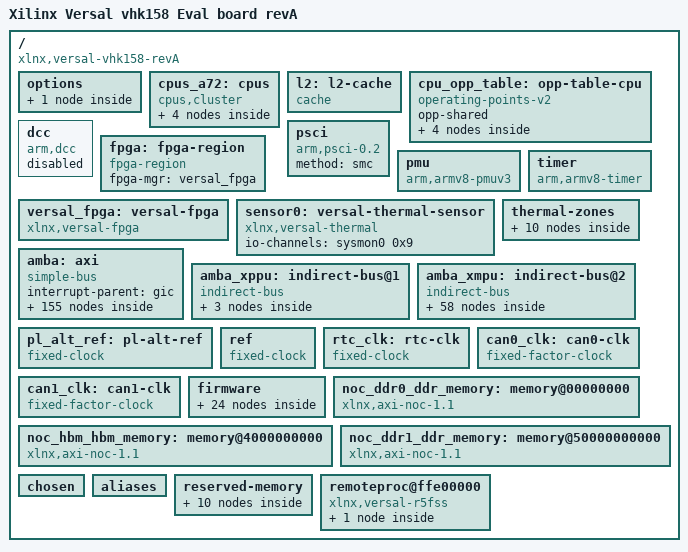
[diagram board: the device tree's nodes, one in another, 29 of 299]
/dts-v1/;
/ {
        speed_grade = "2MP";
        family = "Versal";
        slrcount = <0x2>;
        device_id = "xcvh1582";
        vivado-version = "2026.2";
        board = "vhk158";
        model = "Xilinx Versal vhk158 Eval board revA";
        #size-cells = <0x2>;
        #address-cells = <0x2>;
        compatible = "xlnx,versal-vhk158-revA", "xlnx,versal-vhk158", "xlnx,versal";

        options {

                u-boot {
                        bootscr-address = /bits/ 64 <0x20000000>;
                        compatible = "u-boot,config";
                };
        };

        cpus_a72: cpus {
                phandle = <0xc6>;
                #ranges-size-cells = <0x2>;
                #ranges-address-cells = <0x2>;
                compatible = "cpus,cluster";
                #size-cells = <0x0>;
                #address-cells = <0x1>;

                psv_cortexa72_0: cpu@0 {
                        phandle = <0xbf>;
                        bus-handle = <0x1>;
                        cpu-frequency = <0x5372172a>;
                        xlnx,cpu-clk-freq-hz = <0x5372172a>;
                        xlnx,ip-name = "psv_cortexa72";
                        stamp-frequency = <0x5f5dd19>;
                        xlnx,pss-ref-clk-freq = <0x1fc9f08>;
                        xlnx,timestamp-clk-freq = <0x5f5dd19>;
                        clocks = <&versal_clk 0x4d>;
                        next-level-cache = <&l2>;
                        i-cache-sets = <0x100>;
                        i-cache-line-size = <0x40>;
                        i-cache-size = <0xc000>;
                        d-cache-sets = <0x100>;
                        d-cache-line-size = <0x40>;
                        d-cache-size = <0x8000>;
                        power-domains = <&versal_firmware 0x18110003>;
                        cpu-idle-states = <&CPU_SLEEP_0>;
                        reg = <0x0>;
                        operating-points-v2 = <&cpu_opp_table>;
                        enable-method = "psci";
                        device_type = "cpu";
                        compatible = "arm,cortex-a72", "arm,armv8";
                };

                psv_cortexa72_1: cpu@1 {
                        phandle = <0xc1>;
                        bus-handle = <0x1>;
                        cpu-frequency = <0x5372172a>;
                        xlnx,cpu-clk-freq-hz = <0x5372172a>;
                        xlnx,ip-name = "psv_cortexa72";
                        stamp-frequency = <0x5f5dd19>;
                        xlnx,pss-ref-clk-freq = <0x1fc9f08>;
                        xlnx,timestamp-clk-freq = <0x5f5dd19>;
                        next-level-cache = <&l2>;
                        i-cache-sets = <0x100>;
                        i-cache-line-size = <0x40>;
                        i-cache-size = <0xc000>;
                        d-cache-sets = <0x100>;
                        d-cache-line-size = <0x40>;
                        d-cache-size = <0x8000>;
                        power-domains = <&versal_firmware 0x18110004>;
                        cpu-idle-states = <&CPU_SLEEP_0>;
                        reg = <0x1>;
                        operating-points-v2 = <&cpu_opp_table>;
                        enable-method = "psci";
                        device_type = "cpu";
                        compatible = "arm,cortex-a72", "arm,armv8";
                };

                idle-states {
                        entry-method = "psci";

                        CPU_SLEEP_0: cpu-sleep-0 {
                                phandle = <0x8f>;
                                min-residency-us = <0x2710>;
                                exit-latency-us = <0x258>;
                                entry-latency-us = <0x12c>;
                                local-timer-stop;
                                arm,psci-suspend-param = <0x40000000>;
                                compatible = "arm,idle-state";
                        };
                };
        };

        l2: l2-cache {
                phandle = <0x91>;
                cache-unified;
                cache-sets = <0x1000>;
                cache-line-size = <0x40>;
                cache-size = <0x100000>;
                cache-level = <0x2>;
                compatible = "cache";
        };

        cpu_opp_table: opp-table-cpu {
                phandle = <0x8e>;
                opp-shared;
                compatible = "operating-points-v2";

                opp-1400000000 {
                        opp-microvolt = <0xf4240>;
                        clock-latency-ns = <0x7a120>;
                        opp-hz = /bits/ 64 <0x53724e00>;
                };

                opp-700000000 {
                        opp-microvolt = <0xf4240>;
                        clock-latency-ns = <0x7a120>;
                        opp-hz = /bits/ 64 <0x29b92700>;
                };

                opp-466666667 {
                        opp-microvolt = <0xf4240>;
                        clock-latency-ns = <0x7a120>;
                        opp-hz = /bits/ 64 <0x1bd0c4ab>;
                };

                opp-350000000 {
                        opp-microvolt = <0xf4240>;
                        clock-latency-ns = <0x7a120>;
                        opp-hz = /bits/ 64 <0x14dc9380>;
                };
        };

        dcc: dcc {
                phandle = <0xcf>;
                bootph-all;
                status = "disabled";
                compatible = "arm,dcc";
        };

        fpga: fpga-region {
                phandle = <0xd0>;
                #size-cells = <0x2>;
                #address-cells = <0x2>;
                fpga-mgr = <&versal_fpga>;
                compatible = "fpga-region";
        };

        psci: psci {
                phandle = <0xd1>;
                method = "smc";
                compatible = "arm,psci-0.2";
        };

        pmu: pmu {
                phandle = <0x183>;
                interrupts = <0x1 0x7 0x304>;
                interrupt-parent = <&gic>;
                compatible = "arm,armv8-pmuv3";
        };

        timer: timer {
                phandle = <0xd2>;
                interrupts = <0x1 0xd 0x4 0x1 0xe 0x4 0x1 0xb 0x4 0x1 0xa 0x4>;
                interrupt-parent = <&gic>;
                compatible = "arm,armv8-timer";
        };

        versal_fpga: versal-fpga {
                phandle = <0xa9>;
                compatible = "xlnx,versal-fpga";
        };

        sensor0: versal-thermal-sensor {
                phandle = <0xab>;
                io-channel-names = "sysmon-temp-channel";
                io-channels = <&sysmon0 0x9>;
                #thermal-sensor-cells = <0x1>;
                compatible = "xlnx,versal-thermal";
        };

        thermal-zones {

                versal_thermal: versal-thermal {
                        phandle = <0xd3>;
                        thermal-sensors = <&sensor0 0x0>;
                        polling-delay = <0x3e8>;
                        polling-delay-passive = <0xfa>;

                        trips {

                                temp_alert: temp-alert {
                                        phandle = <0xd4>;
                                        type = "passive";
                                        hysteresis = <0x0>;
                                        temperature = <0x11170>;
                                };

                                ot_crit: ot-crit {
                                        phandle = <0xd5>;
                                        type = "critical";
                                        hysteresis = <0x0>;
                                        temperature = <0x1e848>;
                                };
                        };

                        cooling-maps {
                        };
                };

                versal_thermal_aie: versal-aie-thermal {
                        phandle = <0xd6>;
                        thermal-sensors = <&sensor0 0x1>;
                        polling-delay = <0x3e8>;
                        polling-delay-passive = <0xfa>;

                        trips {

                                temp_alert_aie: temp-alert-aie {
                                        phandle = <0xd7>;
                                        type = "passive";
                                        hysteresis = <0x0>;
                                        temperature = <0x11170>;
                                };

                                ot_crit_aie: ot-crit-aie {
                                        phandle = <0xd8>;
                                        type = "critical";
                                        hysteresis = <0x0>;
                                        temperature = <0x1e848>;
                                };
                        };

                        cooling-maps {
                        };
                };
        };

        amba: axi {
                phandle = <0x1>;
                bootph-all;
                interrupt-parent = <&gic>;
                ranges;
                #size-cells = <0x2>;
                #address-cells = <0x2>;
                compatible = "simple-bus";

                can0: can@ff060000 {
                        phandle = <0xd9>;
                        power-domains = <&versal_firmware 0x1822401f>;
                        clocks = <&can0_clk>,
                         <&versal_clk 0x52>;
                        tx-mailbox-count = <0x20>;
                        rx-fifo-depth = <0x40>;
                        clock-names = "can_clk", "s_axi_aclk";
                        interrupt-parent = <&gic>;
                        interrupts = <0x0 0x14 0x4>;
                        reg = <0x0 0xff060000 0x0 0x6000>;
                        status = "disabled";
                        compatible = "xlnx,canfd-2.0";
                };

                can1: can@ff070000 {
                        phandle = <0xda>;
                        power-domains = <&versal_firmware 0x18224020>;
                        clocks = <&can1_clk>,
                         <&versal_clk 0x52>;
                        tx-mailbox-count = <0x20>;
                        rx-fifo-depth = <0x40>;
                        clock-names = "can_clk", "s_axi_aclk";
                        interrupt-parent = <&gic>;
                        interrupts = <0x0 0x15 0x4>;
                        reg = <0x0 0xff070000 0x0 0x6000>;
                        status = "disabled";
                        compatible = "xlnx,canfd-2.0";
                };

                cci: cci@fd000000 {
                        phandle = <0x60>;
                        xlnx,ip-name = "psv_fpd_maincci";
                        #size-cells = <0x1>;
                        #address-cells = <0x1>;
                        ranges = <0x0 0x0 0xfd000000 0xa0000>;
                        reg = <0x0 0xfd000000 0x0 0x10000>;
                        status = "okay";
                        compatible = "arm,cci-500";

                        cci_pmu: pmu@10000 {
                                phandle = <0xdb>;
                                interrupts = <0x0 0x6a 0x4 0x0 0x6a 0x4 0x0 0x6a 0x4 0x0 0x6a 0x4 0x0 0x6a 0x4 0x0 0x6a 0x4 0x0 0x6a 0x4 0x0 0x6a 0x4>;
                                interrupt-parent = <&gic>;
                                reg = <0x10000 0x90000>;
                                compatible = "arm,cci-500-pmu,r0";
                        };
                };

                lpd_dma_chan0: dma-controller@ffa80000 {
                        phandle = <0x82>;
                        xlnx,dma-mode = <0x1>;
                        xlnx,ip-name = "psv_adma";
                        xlnx,is-cache-coherent = <0x0>;
                        power-domains = <&versal_firmware 0x18224035>;
                        clocks = <&versal_clk 0x51>,
                         <&versal_clk 0x52>;
                        xlnx,bus-width = <0x40>;
                        #dma-cells = <0x1>;
                        xlnx,dma-type = <0x1>;
                        clock-names = "clk_main", "clk_apb";
                        interrupt-parent = <&gic>;
                        interrupts = <0x0 0x3c 0x4>;
                        reg = <0x0 0xffa80000 0x0 0x1000>;
                        status = "okay";
                        compatible = "xlnx,zynqmp-dma-1.0";
                        iommus = <&smmu 0x210>;
                };

                lpd_dma_chan1: dma-controller@ffa90000 {
                        phandle = <0x83>;
                        xlnx,dma-mode = <0x1>;
                        xlnx,ip-name = "psv_adma";
                        xlnx,is-cache-coherent = <0x0>;
                        power-domains = <&versal_firmware 0x18224036>;
                        clocks = <&versal_clk 0x51>,
                         <&versal_clk 0x52>;
                        xlnx,bus-width = <0x40>;
                        #dma-cells = <0x1>;
                        xlnx,dma-type = <0x1>;
                        clock-names = "clk_main", "clk_apb";
                        interrupt-parent = <&gic>;
                        interrupts = <0x0 0x3d 0x4>;
                        reg = <0x0 0xffa90000 0x0 0x1000>;
                        status = "okay";
                        compatible = "xlnx,zynqmp-dma-1.0";
                        iommus = <&smmu 0x212>;
                };

                lpd_dma_chan2: dma-controller@ffaa0000 {
                        phandle = <0x84>;
                        xlnx,dma-mode = <0x1>;
                        xlnx,ip-name = "psv_adma";
                        xlnx,is-cache-coherent = <0x0>;
                        power-domains = <&versal_firmware 0x18224037>;
                        clocks = <&versal_clk 0x51>,
                         <&versal_clk 0x52>;
                        xlnx,bus-width = <0x40>;
                        #dma-cells = <0x1>;
                        xlnx,dma-type = <0x1>;
                        clock-names = "clk_main", "clk_apb";
                        interrupt-parent = <&gic>;
                        interrupts = <0x0 0x3e 0x4>;
                        reg = <0x0 0xffaa0000 0x0 0x1000>;
                        status = "okay";
                        compatible = "xlnx,zynqmp-dma-1.0";
                        iommus = <&smmu 0x214>;
                };

                lpd_dma_chan3: dma-controller@ffab0000 {
                        phandle = <0x85>;
                        xlnx,dma-mode = <0x1>;
                        xlnx,ip-name = "psv_adma";
                        xlnx,is-cache-coherent = <0x0>;
                        power-domains = <&versal_firmware 0x18224038>;
                        clocks = <&versal_clk 0x51>,
                         <&versal_clk 0x52>;
                        xlnx,bus-width = <0x40>;
                        #dma-cells = <0x1>;
                        xlnx,dma-type = <0x1>;
                        clock-names = "clk_main", "clk_apb";
                        interrupt-parent = <&gic>;
                        interrupts = <0x0 0x3f 0x4>;
                        reg = <0x0 0xffab0000 0x0 0x1000>;
                        status = "okay";
                        compatible = "xlnx,zynqmp-dma-1.0";
                        iommus = <&smmu 0x216>;
                };

                lpd_dma_chan4: dma-controller@ffac0000 {
                        phandle = <0x86>;
                        xlnx,dma-mode = <0x1>;
                        xlnx,ip-name = "psv_adma";
                        xlnx,is-cache-coherent = <0x0>;
                        power-domains = <&versal_firmware 0x18224039>;
                        clocks = <&versal_clk 0x51>,
                         <&versal_clk 0x52>;
                        xlnx,bus-width = <0x40>;
                        #dma-cells = <0x1>;
                        xlnx,dma-type = <0x1>;
                        clock-names = "clk_main", "clk_apb";
                        interrupt-parent = <&gic>;
                        interrupts = <0x0 0x40 0x4>;
                        reg = <0x0 0xffac0000 0x0 0x1000>;
                        status = "okay";
                        compatible = "xlnx,zynqmp-dma-1.0";
                        iommus = <&smmu 0x218>;
                };

                lpd_dma_chan5: dma-controller@ffad0000 {
                        phandle = <0x87>;
                        xlnx,dma-mode = <0x1>;
                        xlnx,ip-name = "psv_adma";
                        xlnx,is-cache-coherent = <0x0>;
                        power-domains = <&versal_firmware 0x1822403a>;
                        clocks = <&versal_clk 0x51>,
                         <&versal_clk 0x52>;
                        xlnx,bus-width = <0x40>;
                        #dma-cells = <0x1>;
                        xlnx,dma-type = <0x1>;
                        clock-names = "clk_main", "clk_apb";
                        interrupt-parent = <&gic>;
                        interrupts = <0x0 0x41 0x4>;
                        reg = <0x0 0xffad0000 0x0 0x1000>;
                        status = "okay";
                        compatible = "xlnx,zynqmp-dma-1.0";
                        iommus = <&smmu 0x21a>;
                };

                lpd_dma_chan6: dma-controller@ffae0000 {
                        phandle = <0x88>;
                        xlnx,dma-mode = <0x1>;
                        xlnx,ip-name = "psv_adma";
                        xlnx,is-cache-coherent = <0x0>;
                        power-domains = <&versal_firmware 0x1822403b>;
                        clocks = <&versal_clk 0x51>,
                         <&versal_clk 0x52>;
                        xlnx,bus-width = <0x40>;
                        #dma-cells = <0x1>;
                        xlnx,dma-type = <0x1>;
                        clock-names = "clk_main", "clk_apb";
                        interrupt-parent = <&gic>;
                        interrupts = <0x0 0x42 0x4>;
                        reg = <0x0 0xffae0000 0x0 0x1000>;
                        status = "okay";
                        compatible = "xlnx,zynqmp-dma-1.0";
                        iommus = <&smmu 0x21c>;
                };

                lpd_dma_chan7: dma-controller@ffaf0000 {
                        phandle = <0x89>;
                        xlnx,dma-mode = <0x1>;
                        xlnx,ip-name = "psv_adma";
                        xlnx,is-cache-coherent = <0x0>;
                        power-domains = <&versal_firmware 0x1822403c>;
                        clocks = <&versal_clk 0x51>,
                         <&versal_clk 0x52>;
                        xlnx,bus-width = <0x40>;
                        #dma-cells = <0x1>;
                        xlnx,dma-type = <0x1>;
                        clock-names = "clk_main", "clk_apb";
                        interrupt-parent = <&gic>;
                        interrupts = <0x0 0x43 0x4>;
                        reg = <0x0 0xffaf0000 0x0 0x1000>;
                        status = "okay";
                        compatible = "xlnx,zynqmp-dma-1.0";
                        iommus = <&smmu 0x21e>;
                };

                gem0: ethernet@ff0c0000 {
                        phandle = <0x72>;
                        phy-handle = <0xae>;
                        xlnx,enet-slcr-100mbps-div0 = <0xa>;
                        xlnx,enet-clk-freq-hz = <0x773545d>;
                        xlnx,eth-mode = <0x1>;
                        xlnx,ip-name = "psv_ethernet";
                        xlnx,enet-tsu-clk-freq-hz = <0xee6a8ba>;
                        xlnx,enet-slcr-10mbps-div0 = <0x64>;
                        xlnx,enet-slcr-1000mbps-div0 = <0x2>;
                        phy-mode = "rgmii-id";
                        xlnx,gem-board-interface = "custom";
                        xlnx,is-cache-coherent = <0x0>;
                        xlnx,has-mdio = <0x1>;
                        power-domains = <&versal_firmware 0x18224019>;
                        clocks = <&versal_clk 0x52>,
                         <&versal_clk 0x58>,
                         <&versal_clk 0x31>,
                         <&versal_clk 0x30>,
                         <&versal_clk 0x2b>;
                        #size-cells = <0x0>;
                        #address-cells = <0x1>;
                        clock-names = "pclk", "hclk", "tx_clk", "rx_clk", "tsu_clk";
                        interrupt-parent = <&gic>;
                        interrupts = <0x0 0x38 0x4 0x0 0x38 0x4>;
                        reg = <0x0 0xff0c0000 0x0 0x1000>;
                        status = "okay";
                        compatible = "xlnx,versal-gem", "cdns,gem";
                        iommus = <&smmu 0x234>;

                        mdio: mdio {
                                phandle = <0xdc>;
                                #size-cells = <0x0>;
                                #address-cells = <0x1>;

                                phy1: ethernet-phy@1 {
                                        phandle = <0xae>;
                                        reset-gpios = <&gpio1 0x30 0x1>;
                                        reset-deassert-us = <0x118>;
                                        reset-assert-us = <0x64>;
                                        ti,dp83867-rxctrl-strap-quirk;
                                        ti,fifo-depth = <0x1>;
                                        ti,tx-internal-delay = <0xa>;
                                        ti,rx-internal-delay = <0xb>;
                                        reg = <0x1>;
                                        compatible = "ethernet-phy-id2000.a231";
                                };
                        };
                };

                gem1: ethernet@ff0d0000 {
                        phandle = <0xdd>;
                        power-domains = <&versal_firmware 0x1822401a>;
                        clocks = <&versal_clk 0x52>,
                         <&versal_clk 0x59>,
                         <&versal_clk 0x33>,
                         <&versal_clk 0x32>,
                         <&versal_clk 0x2b>;
                        #size-cells = <0x0>;
                        #address-cells = <0x1>;
                        clock-names = "pclk", "hclk", "tx_clk", "rx_clk", "tsu_clk";
                        interrupt-parent = <&gic>;
                        interrupts = <0x0 0x3a 0x4 0x0 0x3a 0x4>;
                        reg = <0x0 0xff0d0000 0x0 0x1000>;
                        status = "disabled";
                        compatible = "xlnx,versal-gem", "cdns,gem";
                        iommus = <&smmu 0x235>;
                };

                gpio0: gpio@ff0b0000 {
                        phandle = <0xde>;
                        power-domains = <&versal_firmware 0x18224023>;
                        clocks = <&versal_clk 0x52>;
                        interrupt-controller;
                        #interrupt-cells = <0x2>;
                        gpio-controller;
                        #gpio-cells = <0x2>;
                        interrupt-parent = <&gic>;
                        interrupts = <0x0 0xd 0x4>;
                        reg = <0x0 0xff0b0000 0x0 0x1000>;
                        status = "disabled";
                        compatible = "xlnx,versal-gpio-1.0";
                };

                gpio1: gpio@f1020000 {
                        phandle = <0x35>;
                        xlnx,pmc-gpio-emio-peripheral-enable = <0x0>;
                        xlnx,ip-name = "psv_pmc_gpio";
                        power-domains = <&versal_firmware 0x1822402c>;
                        clocks = <&versal_clk 0x3d>;
                        interrupt-controller;
                        #interrupt-cells = <0x2>;
                        gpio-controller;
                        #gpio-cells = <0x2>;
                        interrupt-parent = <&gic>;
                        interrupts = <0x0 0x7a 0x4>;
                        reg = <0x0 0xf1020000 0x0 0x1000>;
                        status = "okay";
                        compatible = "xlnx,pmc-gpio-1.0";
                };

                i2c0: i2c@ff020000 {
                        phandle = <0x6e>;
                        xlnx,iic-board-interface = "custom";
                        xlnx,ip-name = "psv_i2c";
                        xlnx,i2c-clk-freq-hz = <0x5f5dd19>;
                        xlnx,clock-freq = <0x5f5dd19>;
                        power-domains = <&versal_firmware 0x1822401d>;
                        clocks = <&versal_clk 0x62>;
                        #size-cells = <0x0>;
                        #address-cells = <0x1>;
                        clock-frequency = <0x186a0>;
                        interrupt-parent = <&gic>;
                        interrupts = <0x0 0xe 0x4>;
                        reg = <0x0 0xff020000 0x0 0x1000>;
                        status = "okay";
                        compatible = "cdns,i2c-r1p14";
                };

                i2c1: i2c@ff030000 {
                        phandle = <0x6f>;
                        bootph-all;
                        xlnx,iic-board-interface = "custom";
                        xlnx,ip-name = "psv_i2c";
                        xlnx,i2c-clk-freq-hz = <0x5f5dd19>;
                        xlnx,clock-freq = <0x5f5dd19>;
                        power-domains = <&versal_firmware 0x1822401e>;
                        clocks = <&versal_clk 0x63>;
                        #size-cells = <0x0>;
                        #address-cells = <0x1>;
                        clock-frequency = <0x186a0>;
                        interrupt-parent = <&gic>;
                        interrupts = <0x0 0xf 0x4>;
                        reg = <0x0 0xff030000 0x0 0x1000>;
                        status = "okay";
                        compatible = "cdns,i2c-r1p14";

                        eeprom: eeprom@54 {
                                phandle = <0xdf>;
                                bootph-all;
                                reg = <0x54>;
                                compatible = "st,24c128", "atmel,24c128";
                        };
                };

                i2c2: i2c@f1000000 {
                        phandle = <0xe0>;
                        power-domains = <&versal_firmware 0x1822402d>;
                        clocks = <&versal_clk 0x3e>;
                        #size-cells = <0x0>;
                        #address-cells = <0x1>;
                        clock-frequency = <0x186a0>;
                        interrupt-parent = <&gic>;
                        interrupts = <0x0 0x7b 0x4>;
                        reg = <0x0 0xf1000000 0x0 0x1000>;
                        status = "disabled";
                        compatible = "cdns,i2c-r1p14";
                };

                mc0: memory-controller@f6150000 {
                        phandle = <0xe1>;
                        interrupt-parent = <&gic>;
                        interrupts = <0x0 0x93 0x4>;
                        reg-names = "base", "noc";
                        reg = <0x0 0xf6150000 0x0 0x2000 0x0 0xf6070000 0x0 0x20000>;
                        status = "okay";
                        compatible = "xlnx,versal-ddrmc";
                };

                mc1: memory-controller@f62c0000 {
                        phandle = <0xe2>;
                        interrupt-parent = <&gic>;
                        interrupts = <0x0 0x93 0x4>;
                        reg-names = "base", "noc";
                        reg = <0x0 0xf62c0000 0x0 0x2000 0x0 0xf6210000 0x0 0x20000>;
                        status = "okay";
                        compatible = "xlnx,versal-ddrmc";
                };

                mc2: memory-controller@f6430000 {
                        phandle = <0xe3>;
                        interrupt-parent = <&gic>;
                        interrupts = <0x0 0x93 0x4>;
                        reg-names = "base", "noc";
                        reg = <0x0 0xf6430000 0x0 0x2000 0x0 0xf6380000 0x0 0x20000>;
                        status = "disabled";
                        compatible = "xlnx,versal-ddrmc";
                };

                mc3: memory-controller@f65a0000 {
                        phandle = <0xe4>;
                        interrupt-parent = <&gic>;
                        interrupts = <0x0 0x93 0x4>;
                        reg-names = "base", "noc";
                        reg = <0x0 0xf65a0000 0x0 0x2000 0x0 0xf64f0000 0x0 0x20000>;
                        status = "disabled";
                        compatible = "xlnx,versal-ddrmc";
                };

                ocm: memory-controller@ff960000 {
                        phandle = <0xe5>;
                        interrupt-parent = <&gic>;
                        interrupts = <0x0 0xa 0x4>;
                        reg = <0x0 0xff960000 0x0 0x1000>;
                        compatible = "xlnx,zynqmp-ocmc-1.0";
                };

                rtc: rtc@f12a0000 {
                        phandle = <0x47>;
                        xlnx,ip-name = "psv_pmc_rtc";
                        power-domains = <&versal_firmware 0x18224034>;
                        clock-names = "rtc";
                        clocks = <&rtc_clk>;
                        interrupt-parent = <&gic>;
                        interrupts = <0x0 0x8e 0x4 0x0 0x8f 0x4>;
                        interrupt-names = "alarm", "sec";
                        reg = <0x0 0xf12a0000 0x0 0x100>;
                        status = "okay";
                        compatible = "xlnx,zynqmp-rtc";
                };

                sdhci0: mmc@f1040000 {
                        phandle = <0xe6>;
                        power-domains = <&versal_firmware 0x1822402e>;
                        clocks = <&versal_clk 0x3b>,
                         <&versal_clk 0x52>,
                         <&versal_clk 0x4a>;
                        clock-output-names = "clk_out_sd0", "clk_in_sd0";
                        #clock-cells = <0x1>;
                        clock-names = "clk_xin", "clk_ahb", "gate";
                        interrupt-parent = <&gic>;
                        interrupts = <0x0 0x7e 0x4>;
                        reg = <0x0 0xf1040000 0x0 0x10000>;
                        status = "disabled";
                        compatible = "xlnx,versal-8.9a", "arasan,sdhci-8.9a";
                        iommus = <&smmu 0x242>;
                };

                sdhci1: mmc@f1050000 {
                        phandle = <0x36>;
                        no-1-8-v;
                        xlnx,write-protect = <0x0>;
                        xlnx,sdio-clk-freq-hz = <0xbebba31>;
                        xlnx,clk-200-sdr-otap-dly = <0x2>;
                        xlnx,has-power = <0x1>;
                        xlnx,clk-50-ddr-itap-dly = <0x2a>;
                        xlnx,clk-50-sdr-otap-dly = <0x4>;
                        xlnx,slot-type = <0x4>;
                        xlnx,has-cd = <0x1>;
                        xlnx,has-wp = <0x0>;
                        xlnx,card-detect = <0x1>;
                        xlnx,bus-width = <0x8>;
                        xlnx,ip-name = "psv_pmc_sd";
                        xlnx,mio-bank = <0x1>;
                        xlnx,clk-100-sdr-otap-dly = <0x3>;
                        clock-frequency = <0xbebba31>;
                        xlnx,has-emio = <0x0>;
                        xlnx,clk-50-sdr-itap-dly = <0x25>;
                        xlnx,clk-50-ddr-otap-dly = <0x3>;
                        xlnx,is-cache-coherent = <0x0>;
                        xlnx,sd-board-interface = "custom";
                        power-domains = <&versal_firmware 0x1822402f>;
                        clocks = <&versal_clk 0x3c>,
                         <&versal_clk 0x52>,
                         <&versal_clk 0x4a>;
                        clock-output-names = "clk_out_sd1", "clk_in_sd1";
                        #clock-cells = <0x1>;
                        clock-names = "clk_xin", "clk_ahb", "gate";
                        interrupt-parent = <&gic>;
                        interrupts = <0x0 0x80 0x4>;
                        reg = <0x0 0xf1050000 0x0 0x10000>;
                        status = "okay";
                        compatible = "xlnx,versal-8.9a", "arasan,sdhci-8.9a";
                        iommus = <&smmu 0x243>;
                };

                serial0: serial@ff000000 {
                        phandle = <0x6d>;
                        xlnx,clock-freq = <0x5f5dd19>;
                        device_type = "serial";
                        u-boot,dm-pre-reloc;
                        cts-override;
                        xlnx,baudrate = <0x1c200>;
                        xlnx,uart-board-interface = "custom";
                        xlnx,ip-name = "psv_sbsauart";
                        port-number = <0x0>;
                        xlnx,uart-clk-freq-hz = <0x5f5dd19>;
                        xlnx,has-modem = <0x0>;
                        power-domains = <&versal_firmware 0x18224021>;
                        clocks = <&versal_clk 0x5c>,
                         <&versal_clk 0x52>;
                        bootph-all;
                        clock-names = "uartclk", "apb_pclk";
                        reg-io-width = <0x4>;
                        interrupt-parent = <&gic>;
                        interrupts = <0x0 0x12 0x4>;
                        reg = <0x0 0xff000000 0x0 0x1000>;
                        status = "okay";
                        compatible = "arm,pl011", "arm,primecell";
                };

                serial1: serial@ff010000 {
                        phandle = <0xe7>;
                        power-domains = <&versal_firmware 0x18224022>;
                        clocks = <&versal_clk 0x5d>,
                         <&versal_clk 0x52>;
                        bootph-all;
                        clock-names = "uartclk", "apb_pclk";
                        reg-io-width = <0x4>;
                        interrupt-parent = <&gic>;
                        interrupts = <0x0 0x13 0x4>;
                        reg = <0x0 0xff010000 0x0 0x1000>;
                        status = "disabled";
                        compatible = "arm,pl011", "arm,primecell";
                };

                smmu: iommu@fd800000 {
                        phandle = <0x6b>;
                        xlnx,ip-name = "psv_fpd_smmutcu";
                        interrupt-parent = <&gic>;
                        interrupts = <0x0 0x6b 0x4 0x0 0x6b 0x4 0x0 0x6b 0x4 0x0 0x6b 0x4 0x0 0x6b 0x4 0x0 0x6b 0x4 0x0 0x6b 0x4 0x0 0x6b 0x4 0x0 0x6b 0x4 0x0 0x6b 0x4 0x0 0x6b 0x4 0x0 0x6b 0x4 0x0 0x6b 0x4 0x0 0x6b 0x4 0x0 0x6b 0x4 0x0 0x6b 0x4 0x0 0x6b 0x4 0x0 0x6b 0x4 0x0 0x6b 0x4 0x0 0x6b 0x4 0x0 0x6b 0x4 0x0 0x6b 0x4 0x0 0x6b 0x4 0x0 0x6b 0x4 0x0 0x6b 0x4 0x0 0x6b 0x4 0x0 0x6b 0x4 0x0 0x6b 0x4 0x0 0x6b 0x4 0x0 0x6b 0x4 0x0 0x6b 0x4 0x0 0x6b 0x4 0x0 0x6b 0x4>;
                        #global-interrupts = <0x1>;
                        #iommu-cells = <0x1>;
                        stream-match-mask = <0x7c00>;
                        reg = <0x0 0xfd800000 0x0 0x40000>;
                        status = "disabled";
                        compatible = "arm,mmu-500";
                };

                ospi: spi@f1010000 {
                        phandle = <0x34>;
                        num-cs = <0x1>;
                        bus-num = <0x2>;
                        xlnx,ospi-mode = <0x0>;
                        is-dual = <0x0>;
                        xlnx,ospi-clk-freq-hz = <0xbebba31>;
                        xlnx,ip-name = "psv_pmc_ospi";
                        xlnx,clock-freq = <0xbebba31>;
                        xlnx,is-cache-coherent = <0x0>;
                        is-stacked = <0x0>;
                        resets = <&versal_reset 0xc10402e>;
                        reset-names = "qspi";
                        power-domains = <&versal_firmware 0x1822402a>;
                        clocks = <&versal_clk 0x3a>;
                        #size-cells = <0x0>;
                        #address-cells = <0x1>;
                        cdns,trigger-address = <0xc0000000>;
                        cdns,is-dma = <0x1>;
                        cdns,fifo-width = <0x4>;
                        cdns,fifo-depth = <0x100>;
                        interrupt-parent = <&gic>;
                        interrupts = <0x0 0x7c 0x4>;
                        reg = <0x0 0xf1010000 0x0 0x10000 0x0 0xc0000000 0x0 0x20000000>;
                        status = "okay";
                        compatible = "xlnx,versal-ospi-1.0", "cdns,qspi-nor";

                        spi_flash: flash@0 {
                                phandle = <0x2>;
                                reset-gpios = <&gpio1 0xc 0x1>;
                                no-wp;
                                spi-max-frequency = <0x1312d00>;
                                spi-rx-bus-width = <0x8>;
                                spi-tx-bus-width = <0x8>;
                                cdns,tslch-ns = <0x1>;
                                cdns,tchsh-ns = <0x1>;
                                cdns,tsd2d-ns = <0x0>;
                                cdns,tshsl-ns = <0x0>;
                                cdns,read-delay = <0x0>;
                                reg = <0x0>;
                                compatible = "mt35xu02g", "micron,m25p80", "jedec,spi-nor";

                                partitions {
                                        #size-cells = <0x1>;
                                        #address-cells = <0x1>;
                                        compatible = "fixed-partitions";

                                        partition@0 {
                                                reg = <0x0 0x60000>;
                                                label = "Image Selector";
                                        };

                                        partition@60000 {
                                                label = "Image Selector Backup";
                                                reg = <0x60000 0x60000>;
                                        };

                                        partition@c0000 {
                                                label = "Image Selector Scratchpad";
                                                reg = <0xc0000 0x20000>;
                                        };

                                        partition@e0000 {
                                                label = "Image Recovery";
                                                reg = <0xe0000 0x1400000>;
                                        };

                                        partition@14e0000 {
                                                label = "Image Recovery Scratchpad";
                                                reg = <0x14e0000 0x20000>;
                                        };

                                        partition@1500000 {
                                                label = "SystemReady-DT Update Metadata";
                                                reg = <0x1500000 0x20000>;
                                        };

                                        partition@1520000 {
                                                label = "SystemReady-DT Update Metadata Backup";
                                                reg = <0x1520000 0x20000>;
                                        };

                                        partition@1540000 {
                                                label = "U-Boot Variables";
                                                reg = <0x1540000 0x20000>;
                                        };

                                        partition@1560000 {
                                                label = "U-Boot Variables Backup";
                                                reg = <0x1560000 0x20000>;
                                        };

                                        partition@1580000 {
                                                label = "U-Boot UEFI Variables";
                                                reg = <0x1580000 0x40000>;
                                        };

                                        partition@15c0000 {
                                                label = "Bank A Space";
                                                reg = <0x15c0000 0x7200000>;
                                        };

                                        partition@87c0000 {
                                                label = "U-Boot Variables Bank A";
                                                reg = <0x87c0000 0x20000>;
                                        };

                                        partition@87e0000 {
                                                label = "U-Boot Variables Bank A Backup";
                                                reg = <0x87e0000 0x20000>;
                                        };

                                        partition@8800000 {
                                                label = "Bank B Space";
                                                reg = <0x8800000 0x7200000>;
                                        };

                                        partition@fa00000 {
                                                label = "U-Boot Variables Bank B";
                                                reg = <0xfa00000 0x20000>;
                                        };

                                        partition@fa20000 {
                                                label = "U-Boot Variables Bank B Backup";
                                                reg = <0xfa20000 0x20000>;
                                        };

                                        partition@fa40000 {
                                                label = "User Scratchpad";
                                                reg = <0xfa40000 0x5c0000>;
                                        };
                                };
                        };
                };

                qspi: spi@f1030000 {
                        phandle = <0xe8>;
                        power-domains = <&versal_firmware 0x1822402b>;
                        clocks = <&versal_clk 0x39>,
                         <&versal_clk 0x52>;
                        #size-cells = <0x0>;
                        #address-cells = <0x1>;
                        clock-names = "ref_clk", "pclk";
                        interrupt-parent = <&gic>;
                        interrupts = <0x0 0x7d 0x4>;
                        reg = <0x0 0xf1030000 0x0 0x1000>;
                        status = "disabled";
                        compatible = "xlnx,versal-qspi-1.0";
                        iommus = <&smmu 0x244>;
                };

                spi0: spi@ff040000 {
                        phandle = <0xe9>;
                        power-domains = <&versal_firmware 0x1822401b>;
                        clocks = <&versal_clk 0x5e>,
                         <&versal_clk 0x52>;
                        #size-cells = <0x0>;
                        #address-cells = <0x1>;
                        clock-names = "ref_clk", "pclk";
                        interrupt-parent = <&gic>;
                        interrupts = <0x0 0x10 0x4>;
                        reg = <0x0 0xff040000 0x0 0x1000>;
                        status = "disabled";
                        compatible = "cdns,spi-r1p6";
                };

                spi1: spi@ff050000 {
                        phandle = <0xea>;
                        power-domains = <&versal_firmware 0x1822401c>;
                        clocks = <&versal_clk 0x5f>,
                         <&versal_clk 0x52>;
                        #size-cells = <0x0>;
                        #address-cells = <0x1>;
                        clock-names = "ref_clk", "pclk";
                        interrupt-parent = <&gic>;
                        interrupts = <0x0 0x11 0x4>;
                        reg = <0x0 0xff050000 0x0 0x1000>;
                        status = "disabled";
                        compatible = "cdns,spi-r1p6";
                };

                sysmon0: sysmon@f1270000 {
                        phandle = <0x46>;
                        xlnx,sat-5-y = <0x1e46>;
                        xlnx,sat-13-y = <0x65f>;
                        xlnx,sat-5-x = <0x5955>;
                        xlnx,sat-13-x = <0x4517>;
                        xlnx,sat-23-desc = "VNOC , satellite";
                        xlnx,sat-4-desc = "VNOC , satellite";
                        xlnx,sat-1-y = <0x38d>;
                        xlnx,sat-63-y = <0xb4d>;
                        xlnx,sat-11-desc = "Clocking , column , satellite";
                        xlnx,meas-8 = "VP_VN";
                        xlnx,meas-4-slr-number = <0x0>;
                        xlnx,sat-1-x = <0x5f>;
                        xlnx,sat-63-x = <0x5f>;
                        xlnx,meas-7 = "VCC_PSLP";
                        xlnx,sat-25-y = <0x2210>;
                        xlnx,meas-6 = "VCC_PSFP";
                        xlnx,sat-25-x = <0xa4a>;
                        xlnx,sat-26-desc = "Clocking , column , satellite";
                        xlnx,meas-5 = "VCC_PMC";
                        xlnx,sat-7-desc = "Clocking , column , satellite";
                        xlnx,meas-4 = "VCCAUX_PMC";
                        xlnx,sat-14-desc = "VNOC , satellite";
                        xlnx,meas-3 = "VCC_SOC";
                        xlnx,sat-21-y = <0x65f>;
                        xlnx,meas-2 = "VCC_RAM";
                        xlnx,sat-21-x = <0x1c9b>;
                        xlnx,meas-1 = "VCCINT";
                        xlnx,meas-0 = "VCCAUX";
                        xlnx,sat-8-y = <0x1be2>;
                        xlnx,sat-16-y = <0x3670>;
                        xlnx,sat-8-x = <0x69c9>;
                        xlnx,sat-16-x = <0x44d5>;
                        xlnx,sat-17-desc = "VNOC , satellite";
                        xlnx,meas-1-slr-number = <0x0>;
                        xlnx,sat-4-y = <0x1252>;
                        xlnx,sat-12-y = <0x3fa>;
                        xlnx,sat-4-x = <0x5955>;
                        xlnx,sat-12-x = <0x69c9>;
                        xlnx,meas-6-slr-number = <0x0>;
                        xlnx,sat-28-y = <0xfee>;
                        xlnx,sat-21-desc = "VNOC , satellite";
                        xlnx,sat-28-x = <0xa4a>;
                        xlnx,sat-2-desc = "PMC , user , ADC";
                        xlnx,sat-64-desc = "PS , LPD , satellite";
                        xlnx,sat-24-y = <0x3670>;
                        xlnx,sat-24-x = <0x199c>;
                        xlnx,sat-24-desc = "HBM , Satellite , (left)";
                        xlnx,sat-5-desc = "VNOC , satellite";
                        xlnx,sat-19-y = <0x1e46>;
                        xlnx,sat-20-y = <0x3670>;
                        xlnx,sat-12-desc = "Clocking , column , satellite";
                        xlnx,sat-19-x = <0x30d9>;
                        xlnx,sat-20-x = <0x2f36>;
                        xlnx,meas-3-slr-number = <0x0>;
                        xlnx,sat-27-desc = "Clocking , column , satellite";
                        xlnx,sat-7-y = <0x2210>;
                        xlnx,sat-15-y = <0x1e46>;
                        xlnx,sat-7-x = <0x69c9>;
                        xlnx,sat-8-desc = "Clocking , column , satellite";
                        xlnx,sat-15-x = <0x4517>;
                        xlnx,sat-15-desc = "VNOC , satellite";
                        xlnx,meas-8-slr-number = <0x0>;
                        status = "okay";
                        xlnx,sat-3-y = <0x65f>;
                        xlnx,sat-11-y = <0xa29>;
                        xlnx,sat-3-x = <0x5955>;
                        xlnx,sat-11-x = <0x69c9>;
                        xlnx,sat-27-y = <0x161d>;
                        xlnx,sat-27-x = <0xa4a>;
                        xlnx,sat-18-desc = "VNOC , satellite";
                        xlnx,sat-23-y = <0x1e46>;
                        xlnx,meas-0-slr-number = <0x0>;
                        xlnx,sat-23-x = <0x1c9b>;
                        xlnx,sat-22-desc = "VNOC , satellite";
                        xlnx,meas-5-slr-number = <0x0>;
                        xlnx,sat-18-y = <0x1252>;
                        xlnx,sat-3-desc = "VNOC , satellite";
                        xlnx,sat-18-x = <0x30d9>;
                        xlnx,sat-10-desc = "Clocking , column , satellite";
                        xlnx,sat-6-y = <0x3670>;
                        xlnx,sat-14-y = <0x1252>;
                        xlnx,sat-25-desc = "Clocking , column , satellite";
                        xlnx,sat-6-x = <0x5a6e>;
                        xlnx,sat-14-x = <0x4517>;
                        xlnx,sat-6-desc = "HBM , Satellite , (right)";
                        xlnx,meas-8-root-id = <0x8>;
                        xlnx,sat-13-desc = "VNOC , satellite";
                        xlnx,meas-7-root-id = <0x5>;
                        xlnx,sat-2-y = <0x38d>;
                        xlnx,sat-64-y = <0xb4d>;
                        xlnx,sat-10-y = <0xfee>;
                        xlnx,meas-6-root-id = <0x4>;
                        xlnx,sat-2-x = <0x5f>;
                        xlnx,sat-64-x = <0x5f>;
                        xlnx,sat-10-x = <0x69c9>;
                        xlnx,meas-5-root-id = <0x3>;
                        xlnx,sat-26-y = <0x1be2>;
                        xlnx,sat-28-desc = "Clocking , column , satellite";
                        xlnx,meas-4-root-id = <0x1>;
                        xlnx,sat-26-x = <0xa4a>;
                        xlnx,sat-9-desc = "Clocking , column , satellite";
                        xlnx,meas-3-root-id = <0x7>;
                        xlnx,meas-2-slr-number = <0x0>;
                        xlnx,meas-2-root-id = <0x6>;
                        xlnx,sat-16-desc = "HBM , Satellite , (left)";
                        xlnx,ip-name = "psv_pmc_sysmon";
                        xlnx,meas-1-root-id = <0x2>;
                        xlnx,sat-22-y = <0x1252>;
                        xlnx,meas-7-slr-number = <0x0>;
                        xlnx,meas-0-root-id = <0x0>;
                        xlnx,sat-22-x = <0x1c9b>;
                        xlnx,sat-9-y = <0x161d>;
                        xlnx,sat-17-y = <0x65f>;
                        xlnx,sat-19-desc = "VNOC , satellite";
                        xlnx,sat-20-desc = "HBM , Satellite , (right)";
                        xlnx,sat-9-x = <0x69c9>;
                        xlnx,sat-17-x = <0x30d9>;
                        xlnx,sat-1-desc = "PMC , system , ADC";
                        xlnx,sat-63-desc = "PS , FPD , satellite";
                        xlnx,nodeid = <0x18224055>;
                        #size-cells = <0x2>;
                        #address-cells = <0x2>;
                        xlnx,numchannels = [09];
                        interrupts = <0x0 0x90 0x4>;
                        reg = <0x0 0xf1270000 0x0 0x4000>;
                        #io-channel-cells = <0x1>;
                        compatible = "xlnx,versal-sysmon";

                        supply@0 {
                                xlnx,name = "vccaux";
                                reg = <0x0>;
                        };

                        supply@2 {
                                xlnx,name = "vccint";
                                reg = <0x2>;
                        };

                        supply@6 {
                                xlnx,name = "vcc_ram";
                                reg = <0x6>;
                        };

                        supply@7 {
                                xlnx,name = "vcc_soc";
                                reg = <0x7>;
                        };

                        supply@1 {
                                xlnx,name = "vccaux_pmc";
                                reg = <0x1>;
                        };

                        supply@3 {
                                xlnx,name = "vcc_pmc";
                                reg = <0x3>;
                        };

                        supply@4 {
                                xlnx,name = "vcc_psfp";
                                reg = <0x4>;
                        };

                        supply@5 {
                                xlnx,name = "vcc_pslp";
                                reg = <0x5>;
                        };

                        supply@8 {
                                xlnx,name = "vp_vn";
                                reg = <0x8>;
                        };
                };

                sysmon1: sysmon@109270000 {
                        phandle = <0xeb>;
                        xlnx,nodeid = <0x18225055>;
                        #size-cells = <0x0>;
                        #address-cells = <0x1>;
                        xlnx,numchannels = [00];
                        reg = <0x1 0x9270000 0x0 0x4000>;
                        #io-channel-cells = <0x1>;
                        status = "disabled";
                        compatible = "xlnx,versal-sysmon";
                };

                sysmon2: sysmon@111270000 {
                        phandle = <0xec>;
                        xlnx,nodeid = <0x18226055>;
                        #size-cells = <0x0>;
                        #address-cells = <0x1>;
                        xlnx,numchannels = [00];
                        reg = <0x1 0x11270000 0x0 0x4000>;
                        #io-channel-cells = <0x1>;
                        status = "disabled";
                        compatible = "xlnx,versal-sysmon";
                };

                sysmon3: sysmon@119270000 {
                        phandle = <0xed>;
                        xlnx,nodeid = <0x18227055>;
                        #size-cells = <0x0>;
                        #address-cells = <0x1>;
                        xlnx,numchannels = [00];
                        reg = <0x1 0x19270000 0x0 0x4000>;
                        #io-channel-cells = <0x1>;
                        status = "disabled";
                        compatible = "xlnx,versal-sysmon";
                };

                ttc1: timer@ff0f0000 {
                        phandle = <0x74>;
                        xlnx,ttc-clk0-clksrc = <0x0>;
                        xlnx,ttc-clk1-freq-hz = <0x8f0cba9>;
                        xlnx,ttc-clk0-freq-hz = <0x8f0cba9>;
                        xlnx,ip-name = "psv_ttc";
                        xlnx,ttc-clk2-clksrc = <0x0>;
                        xlnx,clock-freq = <0x8f0cba9>;
                        xlnx,ttc-clk1-clksrc = <0x0>;
                        xlnx,ttc-clk2-freq-hz = <0x8f0cba9>;
                        xlnx,ttc-board-interface = "custom";
                        power-domains = <&versal_firmware 0x18224025>;
                        clocks = <&versal_clk 0x28>;
                        timer-width = <0x20>;
                        reg = <0x0 0xff0f0000 0x0 0x1000>;
                        interrupt-parent = <&gic>;
                        interrupts = <0x0 0x28 0x4 0x0 0x29 0x4 0x0 0x2a 0x4>;
                        status = "okay";
                        compatible = "cdns,ttc";
                };

                ttc2: timer@ff100000 {
                        phandle = <0x75>;
                        xlnx,ttc-clk0-clksrc = <0x0>;
                        xlnx,ttc-clk1-freq-hz = <0x8f0cba9>;
                        xlnx,ttc-clk0-freq-hz = <0x8f0cba9>;
                        xlnx,ip-name = "psv_ttc";
                        xlnx,ttc-clk2-clksrc = <0x0>;
                        xlnx,clock-freq = <0x8f0cba9>;
                        xlnx,ttc-clk1-clksrc = <0x0>;
                        xlnx,ttc-clk2-freq-hz = <0x8f0cba9>;
                        xlnx,ttc-board-interface = "custom";
                        power-domains = <&versal_firmware 0x18224026>;
                        clocks = <&versal_clk 0x29>;
                        timer-width = <0x20>;
                        reg = <0x0 0xff100000 0x0 0x1000>;
                        interrupt-parent = <&gic>;
                        interrupts = <0x0 0x2b 0x4 0x0 0x2c 0x4 0x0 0x2d 0x4>;
                        status = "okay";
                        compatible = "uio";
                        linux,uio-name = "libmetal-timer";
                };

                ttc3: timer@ff110000 {
                        phandle = <0x76>;
                        xlnx,ttc-clk0-clksrc = <0x0>;
                        xlnx,ttc-clk1-freq-hz = <0x8f0cba9>;
                        xlnx,ttc-clk0-freq-hz = <0x8f0cba9>;
                        xlnx,ip-name = "psv_ttc";
                        xlnx,ttc-clk2-clksrc = <0x0>;
                        xlnx,clock-freq = <0x8f0cba9>;
                        xlnx,ttc-clk1-clksrc = <0x0>;
                        xlnx,ttc-clk2-freq-hz = <0x8f0cba9>;
                        xlnx,ttc-board-interface = "custom";
                        power-domains = <&versal_firmware 0x18224027>;
                        clocks = <&versal_clk 0x2a>;
                        timer-width = <0x20>;
                        reg = <0x0 0xff110000 0x0 0x1000>;
                        interrupt-parent = <&gic>;
                        interrupts = <0x0 0x2e 0x4 0x0 0x2f 0x4 0x0 0x30 0x4>;
                        status = "okay";
                        compatible = "cdns,ttc";
                };

                usb0: usb@ff9d0000 {
                        phandle = <0x81>;
                        xlnx,ip-name = "psv_usb";
                        resets = <&versal_reset 0xc104036>;
                        power-domains = <&versal_firmware 0x18224018>;
                        clocks = <&versal_clk 0x5b>,
                         <&versal_clk 0x68>;
                        #size-cells = <0x2>;
                        #address-cells = <0x2>;
                        ranges;
                        clock-names = "bus_clk", "ref_clk";
                        reg = <0x0 0xff9d0000 0x0 0x100>;
                        status = "okay";
                        compatible = "xlnx,versal-dwc3";

                        dwc3_0: usb@fe200000 {
                                phandle = <0x6c>;
                                snps,usb3_lpm_capable;
                                maximum-speed = "high-speed";
                                dr_mode = "host";
                                xlnx,enable-superspeed = <0x0>;
                                xlnx,ip-name = "psv_usb_xhci";
                                xlnx,is-cache-coherent = <0x0>;
                                clocks = <&versal_clk 0x5b>;
                                clock-names = "ref";
                                snps,quirk-frame-length-adjustment = <0x20>;
                                snps,dis_u3_susphy_quirk;
                                snps,dis_u2_susphy_quirk;
                                interrupt-parent = <&gic>;
                                interrupts = <0x0 0x16 0x4 0x0 0x16 0x4 0x0 0x1a 0x4 0x0 0x4a 0x4>;
                                interrupt-names = "host", "peripheral", "otg", "wakeup";
                                reg = <0x0 0xfe200000 0x0 0x10000>;
                                status = "okay";
                                compatible = "snps,dwc3";
                                iommus = <&smmu 0x230>;
                        };
                };

                cpm_pciea: pci@fca10000 {
                        phandle = <0xee>;
                        resets = <&versal_reset 0xc410054>;
                        reg-names = "cfg", "cpm_slcr";
                        reg = <0x6 0x0 0x0 0x10000000 0x0 0xfca10000 0x0 0x1000>;
                        msi-map = <0x0 &gic_its 0x0 0x10000>;
                        ranges = <0x2000000 0x0 0xe0010000 0x0 0xe0010000 0x0 0x10000000 0x43000000 0x80 0x0 0x80 0x0 0x0 0x80000000>;
                        bus-range = <0x0 0xff>;
                        interrupt-parent = <&gic>;
                        xlnx,port-type = <0x1>;
                        xlnx,num-of-bars = <0x2>;
                        xlnx,csr-slcr = <0x6 0x0>;
                        interrupts = <0x0 0x48 0x4>;
                        interrupt-names = "misc";
                        interrupt-map-mask = <0x0 0x0 0x0 0x7>;
                        interrupt-map = <0x0 0x0 0x0 0x1 &pcie_intc_0 0x0>,
                         <0x0 0x0 0x0 0x2 &pcie_intc_0 0x1>,
                         <0x0 0x0 0x0 0x3 &pcie_intc_0 0x2>,
                         <0x0 0x0 0x0 0x4 &pcie_intc_0 0x3>;
                        status = "disabled";
                        compatible = "xlnx,versal-cpm-host-1.00";
                        #size-cells = <0x2>;
                        #interrupt-cells = <0x1>;
                        #address-cells = <0x3>;
                        device_type = "pci";

                        pcie_intc_0: interrupt-controller {
                                phandle = <0xb1>;
                                interrupt-controller;
                                #interrupt-cells = <0x1>;
                                #address-cells = <0x0>;
                        };
                };

                cpm5_pcie: pcie@fcdd0000 {
                        phandle = <0xef>;
                        resets = <&versal_reset 0xc410054>;
                        reg-names = "cfg", "cpm_slcr", "cpm_csr";
                        reg = <0x6 0x0 0x0 0x10000000 0x0 0xfcdd0000 0x0 0x1000 0x0 0xfce20000 0x0 0x10000>;
                        msi-map = <0x0 &gic_its 0x0 0x10000>;
                        ranges = <0x2000000 0x0 0xe0000000 0x0 0xe0000000 0x0 0x10000000 0x43000000 0x80 0x0 0x80 0x0 0x0 0x80000000>;
                        bus-range = <0x0 0xff>;
                        interrupt-parent = <&gic>;
                        xlnx,port-type = <0x1>;
                        xlnx,num-of-bars = <0x2>;
                        xlnx,csr-slcr = <0xfce20000>;
                        interrupts = <0x0 0x48 0x4>;
                        interrupt-names = "misc";
                        interrupt-map-mask = <0x0 0x0 0x0 0x7>;
                        interrupt-map = <0x0 0x0 0x0 0x1 &pcie_intc_2 0x0>,
                         <0x0 0x0 0x0 0x2 &pcie_intc_2 0x1>,
                         <0x0 0x0 0x0 0x3 &pcie_intc_2 0x2>,
                         <0x0 0x0 0x0 0x4 &pcie_intc_2 0x3>;
                        status = "disabled";
                        compatible = "xlnx,versal-cpm5-host";
                        #size-cells = <0x2>;
                        #interrupt-cells = <0x1>;
                        #address-cells = <0x3>;
                        device_type = "pci";

                        pcie_intc_2: interrupt-controller {
                                phandle = <0xb2>;
                                interrupt-controller;
                                #interrupt-cells = <0x1>;
                                #address-cells = <0x0>;
                        };
                };

                watchdog: watchdog@fd4d0000 {
                        phandle = <0xf0>;
                        power-domains = <&versal_firmware 0x18224029>;
                        clocks = <&versal_clk 0x4c>;
                        timeout-sec = <0x1e>;
                        interrupt-parent = <&gic>;
                        interrupts = <0x0 0x64 0x1 0x0 0x6d 0x1 0x0 0x6c 0x4 0x0 0x6e 0x4>;
                        interrupt-names = "wdt", "wwdt_reset_pending", "gwdt", "gwdt_reset_pending";
                        reg = <0x0 0xfd4d0000 0x0 0x10000>;
                        status = "disabled";
                        compatible = "xlnx,versal-wwdt";
                };

                watchdog1: watchdog@ff120000 {
                        phandle = <0xf1>;
                        power-domains = <&versal_firmware 0x18224028>;
                        clocks = <&versal_clk 0x52>;
                        timeout-sec = <0x1e>;
                        interrupts = <0x0 0x31 0x1 0x0 0x45 0x1 0x0 0x46 0x4 0x0 0x47 0x4>;
                        interrupt-names = "wdt", "wwdt_reset_pending", "gwdt", "gwdt_reset_pending";
                        interrupt-parent = <&gic>;
                        reg = <0x0 0xff120000 0x0 0x10000>;
                        status = "disabled";
                        compatible = "xlnx,versal-wwdt";
                };

                xilsem_edac: edac@f2014050 {
                        phandle = <0xf2>;
                        reg = <0x0 0xf2014050 0x0 0xc4>;
                        status = "disabled";
                        compatible = "xlnx,versal-xilsem-edac";
                };

                dma0: pmcdma@f11c0000 {
                        phandle = <0x3b>;
                        xlnx,ip-name = "psv_pmc_dma";
                        xlnx,dma-type = <0x1>;
                        reg = <0x0 0xf11c0000 0x0 0x10000>;
                        interrupts = <0x0 0x83 0x4>;
                        interrupt-parent = <&gic>;
                        compatible = "xlnx,zynqmp-csudma-1.0";
                        status = "okay";
                };

                dma1: pmcdma@f11d0000 {
                        phandle = <0x3c>;
                        xlnx,ip-name = "psv_pmc_dma";
                        xlnx,dma-type = <0x2>;
                        reg = <0x0 0xf11d0000 0x0 0x10000>;
                        interrupts = <0x0 0x84 0x4>;
                        interrupt-parent = <&gic>;
                        compatible = "xlnx,zynqmp-csudma-1.0";
                        status = "okay";
                };

                ipi0: mailbox@ff330000 {
                        phandle = <0x9>;
                        reg-names = "ctrl", "msg";
                        ranges;
                        #size-cells = <0x2>;
                        #address-cells = <0x2>;
                        xlnx,ipi-id = <0x2>;
                        reg = <0x0 0xff330000 0x0 0x10000 0x0 0xff3f0400 0x0 0x200>;
                        interrupts = <0x0 0x1e 0x4>;
                        interrupt-parent = <&gic>;
                        compatible = "xlnx,versal-ipi-mailbox";

                        ipi_0_to_ipi_0: child@ff330000 {
                                phandle = <0x111>;
                                reg-names = "ctrl", "msg";
                                reg = <0x0 0xff330000 0x0 0x10000 0x0 0xff3f0400 0x0 0x200>;
                                xlnx,ipi-id = <0x2>;
                                #mbox-cells = <0x1>;
                                compatible = "xlnx,versal-ipi-dest-mailbox";
                        };

                        ipi_0_to_ipi_1: child@ff340000 {
                                phandle = <0x112>;
                                reg-names = "ctrl", "msg";
                                reg = <0x0 0xff340000 0x0 0x10000 0x0 0xff3f0600 0x0 0x200>;
                                xlnx,ipi-id = <0x3>;
                                #mbox-cells = <0x1>;
                                compatible = "xlnx,versal-ipi-dest-mailbox";
                        };

                        ipi_0_to_ipi_2: child@ff350000 {
                                phandle = <0x113>;
                                reg-names = "ctrl", "msg";
                                reg = <0x0 0xff350000 0x0 0x10000 0x0 0xff3f0800 0x0 0x200>;
                                xlnx,ipi-id = <0x4>;
                                #mbox-cells = <0x1>;
                                compatible = "xlnx,versal-ipi-dest-mailbox";
                        };

                        ipi_0_to_ipi_3: child@ff360000 {
                                phandle = <0x114>;
                                reg-names = "ctrl", "msg";
                                reg = <0x0 0xff360000 0x0 0x10000 0x0 0xff3f0a00 0x0 0x200>;
                                xlnx,ipi-id = <0x5>;
                                #mbox-cells = <0x1>;
                                compatible = "xlnx,versal-ipi-dest-mailbox";
                        };

                        ipi_0_to_ipi_4: child@ff370000 {
                                phandle = <0x115>;
                                reg-names = "ctrl", "msg";
                                reg = <0x0 0xff370000 0x0 0x10000 0x0 0xff3f0c00 0x0 0x200>;
                                xlnx,ipi-id = <0x6>;
                                #mbox-cells = <0x1>;
                                compatible = "xlnx,versal-ipi-dest-mailbox";
                        };

                        ipi_0_to_ipi_5: child@ff380000 {
                                phandle = <0x116>;
                                reg-names = "ctrl", "msg";
                                reg = <0x0 0xff380000 0x0 0x10000 0x0 0xff3f0e00 0x0 0x200>;
                                xlnx,ipi-id = <0x7>;
                                #mbox-cells = <0x1>;
                                compatible = "xlnx,versal-ipi-dest-mailbox";
                        };

                        ipi_0_to_ipi_6: child@ff3a0000 {
                                phandle = <0x117>;
                                reg-names = "ctrl";
                                reg = <0x0 0xff3a0000 0x0 0x10000>;
                                xlnx,ipi-id = <0x9>;
                                #mbox-cells = <0x1>;
                                compatible = "xlnx,versal-ipi-dest-mailbox";
                        };

                        ipi_0_to_ipi_pmc: child@ff320000 {
                                phandle = <0x118>;
                                reg-names = "ctrl", "msg";
                                reg = <0x0 0xff320000 0x0 0x10000 0x0 0xff3f0200 0x0 0x200>;
                                xlnx,ipi-id = <0x1>;
                                #mbox-cells = <0x1>;
                                compatible = "xlnx,versal-ipi-dest-mailbox";
                        };

                        ipi_0_to_ipi_pmc_nobuf: child@ff390000 {
                                phandle = <0x119>;
                                reg-names = "ctrl";
                                reg = <0x0 0xff390000 0x0 0x10000>;
                                xlnx,ipi-id = <0x8>;
                                #mbox-cells = <0x1>;
                                compatible = "xlnx,versal-ipi-dest-mailbox";
                        };

                        ipi_0_to_ipi_psm: child@ff310000 {
                                phandle = <0x11a>;
                                reg-names = "ctrl", "msg";
                                reg = <0x0 0xff310000 0x0 0x10000 0x0 0xff3f0000 0x0 0x200>;
                                xlnx,ipi-id = <0x0>;
                                #mbox-cells = <0x1>;
                                compatible = "xlnx,versal-ipi-dest-mailbox";
                        };
                };

                ipi3: mailbox@ff360000 {
                        phandle = <0xa>;
                        reg-names = "ctrl", "msg";
                        ranges;
                        #size-cells = <0x2>;
                        #address-cells = <0x2>;
                        xlnx,ipi-id = <0x5>;
                        reg = <0x0 0xff360000 0x0 0x10000 0x0 0xff3f0a00 0x0 0x200>;
                        interrupts = <0x0 0x21 0x4>;
                        interrupt-parent = <&gic>;
                        compatible = "xlnx,versal-ipi-mailbox";

                        ipi_3_to_ipi_0: child@ff330000 {
                                phandle = <0x12f>;
                                reg-names = "ctrl", "msg";
                                reg = <0x0 0xff330000 0x0 0x10000 0x0 0xff3f0400 0x0 0x200>;
                                xlnx,ipi-id = <0x2>;
                                #mbox-cells = <0x1>;
                                compatible = "xlnx,versal-ipi-dest-mailbox";
                        };

                        ipi_3_to_ipi_1: child@ff340000 {
                                phandle = <0x130>;
                                reg-names = "ctrl", "msg";
                                reg = <0x0 0xff340000 0x0 0x10000 0x0 0xff3f0600 0x0 0x200>;
                                xlnx,ipi-id = <0x3>;
                                #mbox-cells = <0x1>;
                                compatible = "xlnx,versal-ipi-dest-mailbox";
                        };

                        ipi_3_to_ipi_2: child@ff350000 {
                                phandle = <0x131>;
                                reg-names = "ctrl", "msg";
                                reg = <0x0 0xff350000 0x0 0x10000 0x0 0xff3f0800 0x0 0x200>;
                                xlnx,ipi-id = <0x4>;
                                #mbox-cells = <0x1>;
                                compatible = "xlnx,versal-ipi-dest-mailbox";
                        };

                        ipi_3_to_ipi_3: child@ff360000 {
                                phandle = <0x132>;
                                reg-names = "ctrl", "msg";
                                reg = <0x0 0xff360000 0x0 0x10000 0x0 0xff3f0a00 0x0 0x200>;
                                xlnx,ipi-id = <0x5>;
                                #mbox-cells = <0x1>;
                                compatible = "xlnx,versal-ipi-dest-mailbox";
                        };

                        ipi_3_to_ipi_4: child@ff370000 {
                                phandle = <0x133>;
                                reg-names = "ctrl", "msg";
                                reg = <0x0 0xff370000 0x0 0x10000 0x0 0xff3f0c00 0x0 0x200>;
                                xlnx,ipi-id = <0x6>;
                                #mbox-cells = <0x1>;
                                compatible = "xlnx,versal-ipi-dest-mailbox";
                        };

                        ipi_3_to_ipi_5: child@ff380000 {
                                phandle = <0x134>;
                                reg-names = "ctrl", "msg";
                                reg = <0x0 0xff380000 0x0 0x10000 0x0 0xff3f0e00 0x0 0x200>;
                                xlnx,ipi-id = <0x7>;
                                #mbox-cells = <0x1>;
                                compatible = "xlnx,versal-ipi-dest-mailbox";
                        };

                        ipi_3_to_ipi_6: child@ff3a0000 {
                                phandle = <0x135>;
                                reg-names = "ctrl";
                                reg = <0x0 0xff3a0000 0x0 0x10000>;
                                xlnx,ipi-id = <0x9>;
                                #mbox-cells = <0x1>;
                                compatible = "xlnx,versal-ipi-dest-mailbox";
                        };

                        ipi_3_to_ipi_pmc: child@ff320000 {
                                phandle = <0x136>;
                                reg-names = "ctrl", "msg";
                                reg = <0x0 0xff320000 0x0 0x10000 0x0 0xff3f0200 0x0 0x200>;
                                xlnx,ipi-id = <0x1>;
                                #mbox-cells = <0x1>;
                                compatible = "xlnx,versal-ipi-dest-mailbox";
                        };

                        ipi_3_to_ipi_pmc_nobuf: child@ff390000 {
                                phandle = <0x137>;
                                reg-names = "ctrl";
                                reg = <0x0 0xff390000 0x0 0x10000>;
                                xlnx,ipi-id = <0x8>;
                                #mbox-cells = <0x1>;
                                compatible = "xlnx,versal-ipi-dest-mailbox";
                        };

                        ipi_3_to_ipi_psm: child@ff310000 {
                                phandle = <0x138>;
                                reg-names = "ctrl", "msg";
                                reg = <0x0 0xff310000 0x0 0x10000 0x0 0xff3f0000 0x0 0x200>;
                                xlnx,ipi-id = <0x0>;
                                #mbox-cells = <0x1>;
                                compatible = "xlnx,versal-ipi-dest-mailbox";
                        };
                };

                ipi4: mailbox@ff370000 {
                        phandle = <0xb>;
                        reg-names = "ctrl", "msg";
                        ranges;
                        #size-cells = <0x2>;
                        #address-cells = <0x2>;
                        xlnx,ipi-id = <0x6>;
                        reg = <0x0 0xff370000 0x0 0x10000 0x0 0xff3f0c00 0x0 0x200>;
                        interrupts = <0x0 0x22 0x4>;
                        interrupt-parent = <&gic>;
                        compatible = "xlnx,versal-ipi-mailbox";

                        ipi_4_to_ipi_0: child@ff330000 {
                                phandle = <0x139>;
                                reg-names = "ctrl", "msg";
                                reg = <0x0 0xff330000 0x0 0x10000 0x0 0xff3f0400 0x0 0x200>;
                                xlnx,ipi-id = <0x2>;
                                #mbox-cells = <0x1>;
                                compatible = "xlnx,versal-ipi-dest-mailbox";
                        };

                        ipi_4_to_ipi_1: child@ff340000 {
                                phandle = <0x13a>;
                                reg-names = "ctrl", "msg";
                                reg = <0x0 0xff340000 0x0 0x10000 0x0 0xff3f0600 0x0 0x200>;
                                xlnx,ipi-id = <0x3>;
                                #mbox-cells = <0x1>;
                                compatible = "xlnx,versal-ipi-dest-mailbox";
                        };

                        ipi_4_to_ipi_2: child@ff350000 {
                                phandle = <0x13b>;
                                reg-names = "ctrl", "msg";
                                reg = <0x0 0xff350000 0x0 0x10000 0x0 0xff3f0800 0x0 0x200>;
                                xlnx,ipi-id = <0x4>;
                                #mbox-cells = <0x1>;
                                compatible = "xlnx,versal-ipi-dest-mailbox";
                        };

                        ipi_4_to_ipi_3: child@ff360000 {
                                phandle = <0x13c>;
                                reg-names = "ctrl", "msg";
                                reg = <0x0 0xff360000 0x0 0x10000 0x0 0xff3f0a00 0x0 0x200>;
                                xlnx,ipi-id = <0x5>;
                                #mbox-cells = <0x1>;
                                compatible = "xlnx,versal-ipi-dest-mailbox";
                        };

                        ipi_4_to_ipi_4: child@ff370000 {
                                phandle = <0x13d>;
                                reg-names = "ctrl", "msg";
                                reg = <0x0 0xff370000 0x0 0x10000 0x0 0xff3f0c00 0x0 0x200>;
                                xlnx,ipi-id = <0x6>;
                                #mbox-cells = <0x1>;
                                compatible = "xlnx,versal-ipi-dest-mailbox";
                        };

                        ipi_4_to_ipi_5: child@ff380000 {
                                phandle = <0x13e>;
                                reg-names = "ctrl", "msg";
                                reg = <0x0 0xff380000 0x0 0x10000 0x0 0xff3f0e00 0x0 0x200>;
                                xlnx,ipi-id = <0x7>;
                                #mbox-cells = <0x1>;
                                compatible = "xlnx,versal-ipi-dest-mailbox";
                        };

                        ipi_4_to_ipi_6: child@ff3a0000 {
                                phandle = <0x13f>;
                                reg-names = "ctrl";
                                reg = <0x0 0xff3a0000 0x0 0x10000>;
                                xlnx,ipi-id = <0x9>;
                                #mbox-cells = <0x1>;
                                compatible = "xlnx,versal-ipi-dest-mailbox";
                        };

                        ipi_4_to_ipi_pmc: child@ff320000 {
                                phandle = <0x140>;
                                reg-names = "ctrl", "msg";
                                reg = <0x0 0xff320000 0x0 0x10000 0x0 0xff3f0200 0x0 0x200>;
                                xlnx,ipi-id = <0x1>;
                                #mbox-cells = <0x1>;
                                compatible = "xlnx,versal-ipi-dest-mailbox";
                        };

                        ipi_4_to_ipi_pmc_nobuf: child@ff390000 {
                                phandle = <0x141>;
                                reg-names = "ctrl";
                                reg = <0x0 0xff390000 0x0 0x10000>;
                                xlnx,ipi-id = <0x8>;
                                #mbox-cells = <0x1>;
                                compatible = "xlnx,versal-ipi-dest-mailbox";
                        };

                        ipi_4_to_ipi_psm: child@ff310000 {
                                phandle = <0x142>;
                                reg-names = "ctrl", "msg";
                                reg = <0x0 0xff310000 0x0 0x10000 0x0 0xff3f0000 0x0 0x200>;
                                xlnx,ipi-id = <0x0>;
                                #mbox-cells = <0x1>;
                                compatible = "xlnx,versal-ipi-dest-mailbox";
                        };
                };

                ipi5: mailbox@ff380000 {
                        phandle = <0xc>;
                        xlnx,bit-position = <0x7>;
                        xlnx,int-id = <0x43>;
                        reg-names = "ctrl", "msg";
                        xlnx,ipi-target-count = <0xa>;
                        xlnx,ip-name = "psv_ipi";
                        xlnx,buffer-index = <0x7>;
                        xlnx,buffer-base = <0xff3f0e00>;
                        xlnx,cpu-name = "A72";
                        ranges;
                        #size-cells = <0x2>;
                        #address-cells = <0x2>;
                        xlnx,ipi-buf-index = <0x7>;
                        xlnx,ipi-id = <0x7>;
                        xlnx,ipi-bitmask = <0x80>;
                        reg = <0x0 0xff380000 0x0 0x10000 0x0 0xff3f0e00 0x0 0x200>;
                        interrupts = <0x0 0x23 0x4>;
                        interrupt-parent = <&gic>;
                        compatible = "uio";
                        status = "okay";
                        linux,uio-name = "libmetal-ipi";
                        libmetal,uio-ipi-bitmask = <0x10>;

                        ipi_5_to_ipi_0: child@ff330000 {
                                phandle = <0x143>;
                                reg-names = "ctrl", "msg";
                                xlnx,ipi-req-msg-buf = <0xff3f0e80>;
                                xlnx,ipi-buf-index = <0x2>;
                                reg = <0x0 0xff330000 0x0 0x10000 0x0 0xff3f0400 0x0 0x200>;
                                xlnx,ipi-id = <0x2>;
                                #mbox-cells = <0x1>;
                                xlnx,ipi-rsp-msg-buf = <0xff3f0ea0>;
                                xlnx,cpu-name = "A72";
                                xlnx,ipi-bitmask = <0x4>;
                                compatible = "xlnx,versal-ipi-dest-mailbox";
                        };

                        ipi_5_to_ipi_1: child@ff340000 {
                                phandle = <0x144>;
                                reg-names = "ctrl", "msg";
                                xlnx,ipi-req-msg-buf = <0xff3f0ec0>;
                                xlnx,ipi-buf-index = <0x3>;
                                reg = <0x0 0xff340000 0x0 0x10000 0x0 0xff3f0600 0x0 0x200>;
                                xlnx,ipi-id = <0x3>;
                                #mbox-cells = <0x1>;
                                xlnx,ipi-rsp-msg-buf = <0xff3f0ee0>;
                                xlnx,cpu-name = "R5_0";
                                xlnx,ipi-bitmask = <0x8>;
                                compatible = "xlnx,versal-ipi-dest-mailbox";
                        };

                        ipi_5_to_ipi_2: child@ff350000 {
                                phandle = <0x145>;
                                reg-names = "ctrl", "msg";
                                xlnx,ipi-req-msg-buf = <0xff3f0f00>;
                                xlnx,ipi-buf-index = <0x4>;
                                reg = <0x0 0xff350000 0x0 0x10000 0x0 0xff3f0800 0x0 0x200>;
                                xlnx,ipi-id = <0x4>;
                                #mbox-cells = <0x1>;
                                xlnx,ipi-rsp-msg-buf = <0xff3f0f20>;
                                xlnx,cpu-name = "R5_1";
                                xlnx,ipi-bitmask = <0x10>;
                                compatible = "xlnx,versal-ipi-dest-mailbox";
                        };

                        ipi_5_to_ipi_3: child@ff360000 {
                                phandle = <0x146>;
                                reg-names = "ctrl", "msg";
                                xlnx,ipi-req-msg-buf = <0xff3f0f40>;
                                xlnx,ipi-buf-index = <0x5>;
                                reg = <0x0 0xff360000 0x0 0x10000 0x0 0xff3f0a00 0x0 0x200>;
                                xlnx,ipi-id = <0x5>;
                                #mbox-cells = <0x1>;
                                xlnx,ipi-rsp-msg-buf = <0xff3f0f60>;
                                xlnx,cpu-name = "A72";
                                xlnx,ipi-bitmask = <0x20>;
                                compatible = "xlnx,versal-ipi-dest-mailbox";
                        };

                        ipi_5_to_ipi_4: child@ff370000 {
                                phandle = <0x147>;
                                reg-names = "ctrl", "msg";
                                xlnx,ipi-req-msg-buf = <0xff3f0f80>;
                                xlnx,ipi-buf-index = <0x6>;
                                reg = <0x0 0xff370000 0x0 0x10000 0x0 0xff3f0c00 0x0 0x200>;
                                xlnx,ipi-id = <0x6>;
                                #mbox-cells = <0x1>;
                                xlnx,ipi-rsp-msg-buf = <0xff3f0fa0>;
                                xlnx,cpu-name = "A72";
                                xlnx,ipi-bitmask = <0x40>;
                                compatible = "xlnx,versal-ipi-dest-mailbox";
                        };

                        ipi_5_to_ipi_5: child@ff380000 {
                                phandle = <0x148>;
                                reg-names = "ctrl", "msg";
                                xlnx,ipi-req-msg-buf = <0xff3f0fc0>;
                                xlnx,ipi-buf-index = <0x7>;
                                reg = <0x0 0xff380000 0x0 0x10000 0x0 0xff3f0e00 0x0 0x200>;
                                xlnx,ipi-id = <0x7>;
                                #mbox-cells = <0x1>;
                                xlnx,ipi-rsp-msg-buf = <0xff3f0fe0>;
                                xlnx,cpu-name = "A72";
                                xlnx,ipi-bitmask = <0x80>;
                                compatible = "xlnx,versal-ipi-dest-mailbox";
                        };

                        ipi_5_to_ipi_6: child@ff3a0000 {
                                phandle = <0x149>;
                                reg-names = "ctrl";
                                xlnx,ipi-buf-index = <0xffff>;
                                reg = <0x0 0xff3a0000 0x0 0x10000>;
                                xlnx,ipi-id = <0x9>;
                                #mbox-cells = <0x1>;
                                xlnx,cpu-name = "A72";
                                xlnx,ipi-bitmask = <0x200>;
                                compatible = "xlnx,versal-ipi-dest-mailbox";
                        };

                        ipi_5_to_ipi_pmc: child@ff320000 {
                                phandle = <0x14a>;
                                reg-names = "ctrl", "msg";
                                xlnx,ipi-req-msg-buf = <0xff3f0e40>;
                                xlnx,ipi-buf-index = <0x1>;
                                reg = <0x0 0xff320000 0x0 0x10000 0x0 0xff3f0200 0x0 0x200>;
                                xlnx,ipi-id = <0x1>;
                                #mbox-cells = <0x1>;
                                xlnx,ipi-rsp-msg-buf = <0xff3f0e60>;
                                xlnx,cpu-name = "PMC";
                                xlnx,ipi-bitmask = <0x2>;
                                compatible = "xlnx,versal-ipi-dest-mailbox";
                        };

                        ipi_5_to_ipi_pmc_nobuf: child@ff390000 {
                                phandle = <0x14b>;
                                reg-names = "ctrl";
                                xlnx,ipi-buf-index = <0xffff>;
                                reg = <0x0 0xff390000 0x0 0x10000>;
                                xlnx,ipi-id = <0x8>;
                                #mbox-cells = <0x1>;
                                xlnx,cpu-name = "PMC";
                                xlnx,ipi-bitmask = <0x100>;
                                compatible = "xlnx,versal-ipi-dest-mailbox";
                        };

                        ipi_5_to_ipi_psm: child@ff310000 {
                                phandle = <0x14c>;
                                reg-names = "ctrl", "msg";
                                xlnx,ipi-req-msg-buf = <0xff3f0e00>;
                                xlnx,ipi-buf-index = <0x0>;
                                reg = <0x0 0xff310000 0x0 0x10000 0x0 0xff3f0000 0x0 0x200>;
                                xlnx,ipi-id = <0x0>;
                                #mbox-cells = <0x1>;
                                xlnx,ipi-rsp-msg-buf = <0xff3f0e20>;
                                xlnx,cpu-name = "PSM";
                                xlnx,ipi-bitmask = <0x1>;
                                compatible = "xlnx,versal-ipi-dest-mailbox";
                        };
                };

                ipi6: mailbox@ff3a0000 {
                        phandle = <0xd>;
                        reg-names = "ctrl";
                        ranges;
                        #size-cells = <0x2>;
                        #address-cells = <0x2>;
                        xlnx,ipi-id = <0x9>;
                        reg = <0x0 0xff3a0000 0x0 0x10000>;
                        interrupts = <0x0 0x24 0x4>;
                        interrupt-parent = <&gic>;
                        compatible = "xlnx,versal-ipi-mailbox";

                        ipi_6_to_ipi_0: child@ff330000 {
                                phandle = <0x14d>;
                                reg-names = "ctrl", "msg";
                                reg = <0x0 0xff330000 0x0 0x10000 0x0 0xff3f0400 0x0 0x200>;
                                xlnx,ipi-id = <0x2>;
                                #mbox-cells = <0x1>;
                                compatible = "xlnx,versal-ipi-dest-mailbox";
                        };

                        ipi_6_to_ipi_1: child@ff340000 {
                                phandle = <0x14e>;
                                reg-names = "ctrl", "msg";
                                reg = <0x0 0xff340000 0x0 0x10000 0x0 0xff3f0600 0x0 0x200>;
                                xlnx,ipi-id = <0x3>;
                                #mbox-cells = <0x1>;
                                compatible = "xlnx,versal-ipi-dest-mailbox";
                        };

                        ipi_6_to_ipi_2: child@ff350000 {
                                phandle = <0x14f>;
                                reg-names = "ctrl", "msg";
                                reg = <0x0 0xff350000 0x0 0x10000 0x0 0xff3f0800 0x0 0x200>;
                                xlnx,ipi-id = <0x4>;
                                #mbox-cells = <0x1>;
                                compatible = "xlnx,versal-ipi-dest-mailbox";
                        };

                        ipi_6_to_ipi_3: child@ff360000 {
                                phandle = <0x150>;
                                reg-names = "ctrl", "msg";
                                reg = <0x0 0xff360000 0x0 0x10000 0x0 0xff3f0a00 0x0 0x200>;
                                xlnx,ipi-id = <0x5>;
                                #mbox-cells = <0x1>;
                                compatible = "xlnx,versal-ipi-dest-mailbox";
                        };

                        ipi_6_to_ipi_4: child@ff370000 {
                                phandle = <0x151>;
                                reg-names = "ctrl", "msg";
                                reg = <0x0 0xff370000 0x0 0x10000 0x0 0xff3f0c00 0x0 0x200>;
                                xlnx,ipi-id = <0x6>;
                                #mbox-cells = <0x1>;
                                compatible = "xlnx,versal-ipi-dest-mailbox";
                        };

                        ipi_6_to_ipi_5: child@ff380000 {
                                phandle = <0x152>;
                                reg-names = "ctrl", "msg";
                                reg = <0x0 0xff380000 0x0 0x10000 0x0 0xff3f0e00 0x0 0x200>;
                                xlnx,ipi-id = <0x7>;
                                #mbox-cells = <0x1>;
                                compatible = "xlnx,versal-ipi-dest-mailbox";
                        };

                        ipi_6_to_ipi_6: child@ff3a0000 {
                                phandle = <0x153>;
                                reg-names = "ctrl";
                                reg = <0x0 0xff3a0000 0x0 0x10000>;
                                xlnx,ipi-id = <0x9>;
                                #mbox-cells = <0x1>;
                                compatible = "xlnx,versal-ipi-dest-mailbox";
                        };

                        ipi_6_to_ipi_pmc: child@ff320000 {
                                phandle = <0x154>;
                                reg-names = "ctrl", "msg";
                                reg = <0x0 0xff320000 0x0 0x10000 0x0 0xff3f0200 0x0 0x200>;
                                xlnx,ipi-id = <0x1>;
                                #mbox-cells = <0x1>;
                                compatible = "xlnx,versal-ipi-dest-mailbox";
                        };

                        ipi_6_to_ipi_pmc_nobuf: child@ff390000 {
                                phandle = <0x155>;
                                reg-names = "ctrl";
                                reg = <0x0 0xff390000 0x0 0x10000>;
                                xlnx,ipi-id = <0x8>;
                                #mbox-cells = <0x1>;
                                compatible = "xlnx,versal-ipi-dest-mailbox";
                        };

                        ipi_6_to_ipi_psm: child@ff310000 {
                                phandle = <0x156>;
                                reg-names = "ctrl", "msg";
                                reg = <0x0 0xff310000 0x0 0x10000 0x0 0xff3f0000 0x0 0x200>;
                                xlnx,ipi-id = <0x0>;
                                #mbox-cells = <0x1>;
                                compatible = "xlnx,versal-ipi-dest-mailbox";
                        };
                };

                coresight: coresight@f0800000 {
                        phandle = <0x14>;
                        xlnx,ip-name = "psv_coresight";
                        reg = <0x0 0xf0800000 0x0 0x10000>;
                        status = "okay";
                        compatible = "xlnx,coresight-1.0";
                };

                CIPS_0_pspmc_0_psv_coresight_fpd_cti1b: CIPS_0_pspmc_0_psv_coresight_fpd_cti1b@f0bb0000 {
                        phandle = <0x1c>;
                        reg = <0x0 0xf0bb0000 0x0 0x10000>;
                        xlnx,ip-name = "psv_coresight_fpd_cti1b";
                        status = "okay";
                        compatible = "xlnx,psv-coresight-fpd-cti1b-1.0";
                };

                CIPS_0_pspmc_0_psv_coresight_fpd_cti1c: CIPS_0_pspmc_0_psv_coresight_fpd_cti1c@f0bc0000 {
                        phandle = <0x1d>;
                        reg = <0x0 0xf0bc0000 0x0 0x10000>;
                        xlnx,ip-name = "psv_coresight_fpd_cti1c";
                        status = "okay";
                        compatible = "xlnx,psv-coresight-fpd-cti1c-1.0";
                };

                CIPS_0_pspmc_0_psv_coresight_fpd_cti1d: CIPS_0_pspmc_0_psv_coresight_fpd_cti1d@f0bd0000 {
                        phandle = <0x1e>;
                        reg = <0x0 0xf0bd0000 0x0 0x10000>;
                        xlnx,ip-name = "psv_coresight_fpd_cti1d";
                        status = "okay";
                        compatible = "xlnx,psv-coresight-fpd-cti1d-1.0";
                };

                CIPS_0_pspmc_0_psv_coresight_lpd_cti: CIPS_0_pspmc_0_psv_coresight_lpd_cti@f09d0000 {
                        phandle = <0x17>;
                        reg = <0x0 0xf09d0000 0x0 0x10000>;
                        xlnx,ip-name = "psv_coresight_lpd_cti";
                        status = "okay";
                        compatible = "xlnx,psv-coresight-lpd-cti-1.0";
                };

                CIPS_0_pspmc_0_psv_coresight_pmc_cti: CIPS_0_pspmc_0_psv_coresight_pmc_cti@f08d0000 {
                        phandle = <0x15>;
                        reg = <0x0 0xf08d0000 0x0 0x10000>;
                        xlnx,ip-name = "psv_coresight_pmc_cti";
                        status = "okay";
                        compatible = "xlnx,psv-coresight-pmc-cti-1.0";
                };

                CIPS_0_pspmc_0_psv_coresight_r50_cti: CIPS_0_pspmc_0_psv_coresight_r50_cti@f0a10000 {
                        phandle = <0x18>;
                        reg = <0x0 0xf0a10000 0x0 0x10000>;
                        xlnx,ip-name = "psv_coresight_r50_cti";
                        status = "okay";
                        compatible = "xlnx,psv-coresight-r50-cti-1.0";
                };

                CIPS_0_pspmc_0_psv_coresight_r51_cti: CIPS_0_pspmc_0_psv_coresight_r51_cti@f0a50000 {
                        phandle = <0x19>;
                        reg = <0x0 0xf0a50000 0x0 0x10000>;
                        xlnx,ip-name = "psv_coresight_r51_cti";
                        status = "okay";
                        compatible = "xlnx,psv-coresight-r51-cti-1.0";
                };

                CIPS_0_pspmc_0_psv_cpm: CIPS_0_pspmc_0_psv_cpm@0 {
                        phandle = <0x5f>;
                        xlnx,cpm5-dma0-csr-addr = <0xfce20000>;
                        xlnx,cpm-slcr = <0xfca10000>;
                        reg = <0x0 0xfc000000 0x0 0x1000000>;
                        xlnx,ip-name = "psv_cpm";
                        status = "okay";
                        compatible = "xlnx,psv-cpm-1.0";
                        xlnx,cpm5-slcr-addr = <0xfcdd0000>;
                };

                CIPS_0_pspmc_0_psv_pmc_analog_0: CIPS_0_pspmc_0_psv_pmc_analog_0@f1160000 {
                        phandle = <0x39>;
                        xlnx,cram-scan = <0x0>;
                        xlnx,event-log = <0x0>;
                        xlnx,npi-scan = <0x0>;
                        reg = <0x0 0xf1160000 0x0 0x30000>;
                        xlnx,ip-name = "psv_pmc_analog";
                        status = "okay";
                        compatible = "xlnx,psv-pmc-analog-1.0";
                };

                CIPS_0_pspmc_0_psv_pmc_iou_slcr_0: CIPS_0_pspmc_0_psv_pmc_iou_slcr_0@f1060000 {
                        phandle = <0x37>;
                        reg = <0x0 0xf1060000 0x0 0x10000>;
                        xlnx,ip-name = "psv_pmc_iou_slcr";
                        status = "okay";
                        compatible = "xlnx,psv-pmc-iou-slcr-1.0";
                };

                CIPS_0_pspmc_0_psv_pmc_tap: CIPS_0_pspmc_0_psv_pmc_tap@f11a0000 {
                        phandle = <0x3a>;
                        reg = <0x0 0xf11a0000 0x0 0x20000>;
                        xlnx,ip-name = "psv_pmc_tap";
                        status = "okay";
                        compatible = "xlnx,psv-pmc-tap-1.0";
                };

                libmetal_uio_desc099c8000: libmetal_uio_desc0@99c8000 {
                        phandle = <0x185>;
                        reg = <0x0 0x99c8000 0x0 0x4000>;
                        compatible = "uio";
                        linux,uio-name = "libmetal-desc0";
                };

                libmetal_uio_desc199cc000: libmetal_uio_desc1@99cc000 {
                        phandle = <0x186>;
                        reg = <0x0 0x99cc000 0x0 0x4000>;
                        compatible = "uio";
                        linux,uio-name = "libmetal-desc1";
                };

                libmetal_uio_data99d0000: libmetal_uio_data@99d0000 {
                        phandle = <0x187>;
                        reg = <0x0 0x99d0000 0x0 0x40000>;
                        compatible = "uio";
                        linux,uio-name = "libmetal-data";
                };

                gic: interrupt-controller@f9000000 {
                        phandle = <0x5e>;
                        compatible = "arm,gic-v3";
                        #interrupt-cells = <0x3>;
                        #address-cells = <0x2>;
                        #size-cells = <0x2>;
                        ranges;
                        reg = <0x0 0xf9000000 0x0 0x80000 0x0 0xf9080000 0x0 0x80000>;
                        interrupt-controller;
                        interrupt-parent = <&gic>;
                        interrupts = <0x1 0x9 0x4>;
                        status = "okay";
                        xlnx,apu-gic-its-ctl = <0xf9020000>;
                        xlnx,ip-name = "psv_acpu_gic";

                        gic_its: msi-controller@f9020000 {
                                phandle = <0x8>;
                                compatible = "arm,gic-v3-its";
                                status = "okay";
                                msi-controller;
                                #msi-cells = <0x1>;
                                reg = <0x0 0xf9020000 0x0 0x20000>;
                        };
                };
        };

        amba_xppu: indirect-bus@1 {
                phandle = <0x163>;
                #size-cells = <0x2>;
                #address-cells = <0x2>;
                compatible = "indirect-bus";

                lpd_xppu: xppu@ff990000 {
                        phandle = <0x7e>;
                        xlnx,ip-name = "psv_lpd_xppu";
                        status = "okay";
                        reg = <0x0 0xff990000 0x0 0x2000>;
                        #firewall-cells = <0x0>;
                        compatible = "xlnx,xppu";
                };

                pmc_xppu: xppu@f1310000 {
                        phandle = <0x5b>;
                        xlnx,ip-name = "psv_pmc_xppu";
                        status = "okay";
                        reg = <0x0 0xf1310000 0x0 0x2000>;
                        #firewall-cells = <0x0>;
                        compatible = "xlnx,xppu";
                };

                pmc_xppu_npi: xppu@f1300000 {
                        phandle = <0x5a>;
                        xlnx,ip-name = "psv_pmc_xppu_npi";
                        status = "okay";
                        reg = <0x0 0xf1300000 0x0 0x2000>;
                        #firewall-cells = <0x0>;
                        compatible = "xlnx,xppu";
                };
        };

        amba_xmpu: indirect-bus@2 {
                phandle = <0x164>;
                #size-cells = <0x2>;
                #address-cells = <0x2>;
                compatible = "indirect-bus";

                fpd_xmpu: xmpu@fd390000 {
                        phandle = <0x64>;
                        xlnx,ip-name = "psv_fpd_slave_xmpu";
                        status = "okay";
                        reg = <0x0 0xfd390000 0x0 0x1000>;
                        #firewall-cells = <0x0>;
                        compatible = "xlnx,xmpu";
                };

                pmc_xmpu: xmpu@f12f0000 {
                        phandle = <0x59>;
                        xlnx,ip-name = "psv_pmc_xmpu";
                        status = "okay";
                        reg = <0x0 0xf12f0000 0x0 0x1000>;
                        #firewall-cells = <0x0>;
                        compatible = "xlnx,xmpu";
                };

                ocm_xmpu: xmpu@ff980000 {
                        phandle = <0x7d>;
                        xlnx,ip-name = "psv_ocm_xmpu";
                        status = "okay";
                        reg = <0x0 0xff980000 0x0 0x1000>;
                        #firewall-cells = <0x0>;
                        compatible = "xlnx,xmpu";
                };

                ddrmc_xmpu_0: xmpu@f6080000 {
                        phandle = <0x165>;
                        status = "disabled";
                        reg = <0x0 0xf6080000 0x0 0x1000>;
                        #firewall-cells = <0x0>;
                        compatible = "xlnx,xmpu";
                };

                ddrmc_xmpu_1: xmpu@f6220000 {
                        phandle = <0x166>;
                        status = "disabled";
                        reg = <0x0 0xf6220000 0x0 0x1000>;
                        #firewall-cells = <0x0>;
                        compatible = "xlnx,xmpu";
                };

                ddrmc_xmpu_2: xmpu@f6390000 {
                        phandle = <0x167>;
                        status = "disabled";
                        reg = <0x0 0xf6390000 0x0 0x1000>;
                        #firewall-cells = <0x0>;
                        compatible = "xlnx,xmpu";
                };

                ddrmc_xmpu_3: xmpu@f6500000 {
                        phandle = <0x168>;
                        status = "disabled";
                        reg = <0x0 0xf6500000 0x0 0x1000>;
                        #firewall-cells = <0x0>;
                        compatible = "xlnx,xmpu";
                };

                fpd_funnel: fpd-funnel@f0b20000 {
                        phandle = <0x169>;
                        clocks = <&versal_clk 0x52>;
                        status = "disabled";
                        clock-names = "apb_pclk";
                        reg = <0x0 0xf0b20000 0x0 0x1000>;
                        compatible = "arm,coresight-dynamic-funnel", "arm,primecell";

                        in-ports {
                                #size-cells = <0x0>;
                                #address-cells = <0x1>;

                                port@1 {
                                        reg = <0x1>;

                                        fpd_funnel_in_port1: endpoint {
                                                phandle = <0xbe>;
                                                remote-endpoint = <&apu_etf_out_port>;
                                        };
                                };
                        };

                        out-ports {

                                port {

                                        fpd_funnel_out_port: endpoint {
                                                phandle = <0xb5>;
                                                remote-endpoint = <&fpd_etf_in_port>;
                                        };
                                };
                        };
                };

                fpd_etf: fpd-etf@f0b30000 {
                        phandle = <0x16a>;
                        clocks = <&versal_clk 0x52>;
                        status = "disabled";
                        clock-names = "apb_pclk";
                        reg = <0x0 0xf0b30000 0x0 0x1000>;
                        compatible = "arm,coresight-tmc", "arm,primecell";

                        in-ports {

                                port {

                                        fpd_etf_in_port: endpoint {
                                                phandle = <0xb4>;
                                                remote-endpoint = <&fpd_funnel_out_port>;
                                        };
                                };
                        };

                        out-ports {

                                port {

                                        fpd_etf_out_port: endpoint {
                                                phandle = <0xb7>;
                                                remote-endpoint = <&replicator_in_port>;
                                        };
                                };
                        };
                };

                replicator: replicator@f0b40000 {
                        phandle = <0x16b>;
                        clocks = <&versal_clk 0x52>;
                        status = "disabled";
                        clock-names = "apb_pclk";
                        reg = <0x0 0xf0b40000 0x0 0x1000>;
                        compatible = "arm,coresight-dynamic-replicator", "arm,primecell";

                        in-ports {

                                port {

                                        replicator_in_port: endpoint {
                                                phandle = <0xb6>;
                                                remote-endpoint = <&fpd_etf_out_port>;
                                        };
                                };
                        };

                        out-ports {
                                #size-cells = <0x0>;
                                #address-cells = <0x1>;

                                port@0 {
                                        reg = <0x0>;

                                        replicator_out_port0: endpoint {
                                                phandle = <0xb9>;
                                                remote-endpoint = <&etr_in_port>;
                                        };
                                };
                        };
                };

                etr: etr@f0b50000 {
                        phandle = <0x16c>;
                        clocks = <&versal_clk 0x52>;
                        status = "disabled";
                        clock-names = "apb_pclk";
                        reg = <0x0 0xf0b50000 0x0 0x1000>;
                        compatible = "arm,coresight-tmc", "arm,primecell";

                        in-ports {

                                port {

                                        etr_in_port: endpoint {
                                                phandle = <0xb8>;
                                                remote-endpoint = <&replicator_out_port0>;
                                        };
                                };
                        };
                };

                apu_funnel: funnel@f0c20000 {
                        phandle = <0x16d>;
                        clocks = <&versal_clk 0x52>;
                        status = "disabled";
                        clock-names = "apb_pclk";
                        reg = <0x0 0xf0c20000 0x0 0x1000>;
                        compatible = "arm,coresight-dynamic-funnel", "arm,primecell";

                        in-ports {
                                #size-cells = <0x0>;
                                #address-cells = <0x1>;

                                port@0 {
                                        reg = <0x0>;

                                        funnel_in_port0: endpoint {
                                                phandle = <0xc0>;
                                                remote-endpoint = <&etm0_out_port>;
                                        };
                                };

                                port@1 {
                                        reg = <0x1>;

                                        funnel_in_port1: endpoint {
                                                phandle = <0xc2>;
                                                remote-endpoint = <&etm1_out_port>;
                                        };
                                };
                        };

                        out-ports {

                                port {

                                        funnel_out_port: endpoint {
                                                phandle = <0xbd>;
                                                remote-endpoint = <&etf_in_port>;
                                        };
                                };
                        };
                };

                apu_etf: etf@f0c30000 {
                        phandle = <0x16e>;
                        clocks = <&versal_clk 0x52>;
                        status = "disabled";
                        clock-names = "apb_pclk";
                        reg = <0x0 0xf0c30000 0x0 0x1000>;
                        compatible = "arm,coresight-tmc", "arm,primecell";

                        in-ports {

                                port {

                                        etf_in_port: endpoint {
                                                phandle = <0xbc>;
                                                remote-endpoint = <&funnel_out_port>;
                                        };
                                };
                        };

                        out-ports {

                                port {

                                        apu_etf_out_port: endpoint {
                                                phandle = <0xb3>;
                                                remote-endpoint = <&fpd_funnel_in_port1>;
                                        };
                                };
                        };
                };

                cpu0_debug: cpu0-debug@f0d00000 {
                        phandle = <0x16f>;
                        clocks = <&versal_clk 0x52>;
                        status = "disabled";
                        cpu = <&psv_cortexa72_0>;
                        clock-names = "apb_pclk";
                        reg = <0x0 0xf0d00000 0x0 0x1000>;
                        compatible = "arm,coresight-cpu-debug", "arm,primecell";
                };

                etm0: etm@f0d30000 {
                        phandle = <0x170>;
                        clocks = <&versal_clk 0x52>;
                        status = "disabled";
                        cpu = <&psv_cortexa72_0>;
                        clock-names = "apb_pclk";
                        reg = <0x0 0xf0d30000 0x0 0x1000>;
                        compatible = "arm,coresight-etm4x", "arm,primecell";

                        out-ports {

                                port {

                                        etm0_out_port: endpoint {
                                                phandle = <0xba>;
                                                remote-endpoint = <&funnel_in_port0>;
                                        };
                                };
                        };
                };

                cpu1_debug: cpu1-debug@f0d40000 {
                        phandle = <0x171>;
                        clocks = <&versal_clk 0x52>;
                        status = "disabled";
                        cpu = <&psv_cortexa72_1>;
                        clock-names = "apb_pclk";
                        reg = <0x0 0xf0d40000 0x0 0x1000>;
                        compatible = "arm,coresight-cpu-debug", "arm,primecell";
                };

                etm1: etm@f0d70000 {
                        phandle = <0x172>;
                        clocks = <&versal_clk 0x52>;
                        status = "disabled";
                        cpu = <&psv_cortexa72_1>;
                        clock-names = "apb_pclk";
                        reg = <0x0 0xf0d70000 0x0 0x1000>;
                        compatible = "arm,coresight-etm4x", "arm,primecell";

                        out-ports {

                                port {

                                        etm1_out_port: endpoint {
                                                phandle = <0xbb>;
                                                remote-endpoint = <&funnel_in_port1>;
                                        };
                                };
                        };
                };
        };

        pl_alt_ref: pl-alt-ref {
                phandle = <0xc4>;
                clock-output-names = "pl_alt_ref_clk";
                clock-frequency = <0x1fca055>;
                #clock-cells = <0x0>;
                compatible = "fixed-clock";
                bootph-all;
        };

        ref: ref {
                phandle = <0xc3>;
                clock-output-names = "ref_clk";
                clock-frequency = <0x1fca055>;
                #clock-cells = <0x0>;
                compatible = "fixed-clock";
                bootph-all;
        };

        rtc_clk: rtc-clk {
                phandle = <0xaf>;
                clock-output-names = "rtc_clk";
                clock-frequency = <0x8000>;
                #clock-cells = <0x0>;
                compatible = "fixed-clock";
                bootph-all;
        };

        can0_clk: can0-clk {
                phandle = <0xac>;
                clock-output-names = "can0_clk";
                clock-mult = <0x1>;
                clock-div = <0x2>;
                clocks = <&versal_clk 0x60>;
                compatible = "fixed-factor-clock";
                #clock-cells = <0x0>;
        };

        can1_clk: can1-clk {
                phandle = <0xad>;
                clock-output-names = "can1_clk";
                clock-mult = <0x1>;
                clock-div = <0x2>;
                clocks = <&versal_clk 0x61>;
                compatible = "fixed-factor-clock";
                #clock-cells = <0x0>;
        };

        firmware {

                versal_firmware: versal-firmware {
                        phandle = <0x90>;
                        #power-domain-cells = <0x1>;
                        method = "smc";
                        bootph-all;
                        interrupt-parent = <&gic>;
                        compatible = "xlnx,versal-firmware";

                        versal_clk: clock-controller {
                                phandle = <0x92>;
                                clock-names = "ref", "pl_alt_ref";
                                clocks = <&ref>,
                                 <&pl_alt_ref>;
                                compatible = "xlnx,versal-clk";
                                #clock-cells = <0x1>;
                                bootph-all;
                        };

                        zynqmp_power: power-management {
                                phandle = <0x173>;
                                compatible = "xlnx,zynqmp-power";
                        };

                        versal_reset: reset-controller {
                                phandle = <0xb0>;
                                #reset-cells = <0x1>;
                                compatible = "xlnx,versal-reset";
                        };

                        pinctrl0: pinctrl {
                                phandle = <0x174>;
                                compatible = "xlnx,versal-pinctrl";
                        };

                        versal_sec_cfg: versal-sec-cfg {
                                phandle = <0x175>;
                                compatible = "xlnx,versal-sec-cfg";

                                nvmem-layout {
                                        #size-cells = <0x1>;
                                        #address-cells = <0x1>;
                                        compatible = "fixed-layout";

                                        bbram_zeroize: bbram-zeroize@4 {
                                                phandle = <0x176>;
                                                reg = <0x4 0x4>;
                                        };

                                        bbram_key: bbram-key@10 {
                                                phandle = <0x177>;
                                                reg = <0x10 0x20>;
                                        };

                                        bbram_usr: bbram-usr@30 {
                                                phandle = <0x178>;
                                                reg = <0x30 0x4>;
                                        };

                                        bbram_lock: bbram-lock@48 {
                                                phandle = <0x179>;
                                                reg = <0x48 0x4>;
                                        };

                                        user_key0: user-key@110 {
                                                phandle = <0x17a>;
                                                reg = <0x110 0x20>;
                                        };

                                        user_key1: user-key@130 {
                                                phandle = <0x17b>;
                                                reg = <0x130 0x20>;
                                        };

                                        user_key2: user-key@150 {
                                                phandle = <0x17c>;
                                                reg = <0x150 0x20>;
                                        };

                                        user_key3: user-key@170 {
                                                phandle = <0x17d>;
                                                reg = <0x170 0x20>;
                                        };

                                        user_key4: user-key@190 {
                                                phandle = <0x17e>;
                                                reg = <0x190 0x20>;
                                        };

                                        user_key5: user-key@1b0 {
                                                phandle = <0x17f>;
                                                reg = <0x1b0 0x20>;
                                        };

                                        user_key6: user-key@1d0 {
                                                phandle = <0x180>;
                                                reg = <0x1d0 0x20>;
                                        };

                                        user_key7: user-key@1f0 {
                                                phandle = <0x181>;
                                                reg = <0x1f0 0x20>;
                                        };
                                };
                        };
                };

                fwu-mdata {
                        compatible = "u-boot,fwu-mdata-mtd";
                        fwu-mdata-store = <&spi_flash>;
                        mdata-parts = "SystemReady-DT Update Metadata", "SystemReady-DT Update Metadata Backup";

                        fwu-bank0 {
                                id = <0x0>;
                                label = "Bank A Space";

                                fwu-image0 {
                                        id = <0x0>;
                                        offset = <0x0>;
                                        size = <0x7200000>;
                                        uuid = "0b931b7e-b2f6-11ef-8565-eb65d140066b";
                                };
                        };

                        fwu-bank1 {
                                id = <0x1>;
                                label = "Bank B Space";

                                fwu-image0 {
                                        id = <0x0>;
                                        offset = <0x0>;
                                        size = <0x7200000>;
                                        uuid = "1243d800-b2f6-11ef-8f4f-8bddc3aa326d";
                                };
                        };
                };
        };

        noc_ddr0_ddr_memory: memory@00000000 {
                phandle = <0x5>;
                memory_type = "memory";
                reg = <0x0 0x0 0x0 0x80000000 0x8 0x0 0x3 0x80000000>;
                device_type = "memory";
                xlnx,ip-name = "axi_noc";
                compatible = "xlnx,axi-noc-1.1";
        };

        noc_hbm_hbm_memory: memory@4000000000 {
                phandle = <0x7>;
                memory_type = "memory";
                reg = <0x40 0x0 0x8 0x0>;
                device_type = "memory";
                xlnx,ip-name = "axi_noc";
                compatible = "xlnx,axi-noc-1.1";
        };

        noc_ddr1_ddr_memory: memory@50000000000 {
                phandle = <0x6>;
                memory_type = "memory";
                reg = <0x500 0x0 0x4 0x0>;
                device_type = "memory";
                xlnx,ip-name = "axi_noc";
                compatible = "xlnx,axi-noc-1.1";
        };

        chosen {
                bootargs = "console=ttyAMA0 earlycon=pl011,mmio32,0xFF000000,115200n8 clk_ignore_unused";
                stdout-path = "serial0:115200";
        };

        aliases {
                nvmem0 = "/axi/i2c@ff030000/eeprom@54";
                rtc0 = "/axi/rtc@f12a0000";
                usb0 = "/axi/usb@ff9d0000";
                mmc0 = "/axi/mmc@f1050000";
                ethernet0 = "/axi/ethernet@ff0c0000";
                i2c1 = "/axi/i2c@ff030000";
                i2c0 = "/axi/i2c@ff020000";
                serial2 = "/dcc";
                spi0 = "/axi/spi@f1010000";
                serial0 = "/axi/serial@ff000000";
        };

        __symbols__ {
                psv_cortexa72_0 = "/cpus/cpu@0";
                psv_cortexa72_1 = "/cpus/cpu@1";
                CPU_SLEEP_0 = "/cpus/idle-states/cpu-sleep-0";
                cpus_a72 = "/cpus";
                l2 = "/l2-cache";
                cpu_opp_table = "/opp-table-cpu";
                dcc = "/dcc";
                fpga = "/fpga-region";
                psci = "/psci";
                pmu = "/pmu";
                timer = "/timer";
                versal_fpga = "/versal-fpga";
                sensor0 = "/versal-thermal-sensor";
                temp_alert = "/thermal-zones/versal-thermal/trips/temp-alert";
                ot_crit = "/thermal-zones/versal-thermal/trips/ot-crit";
                versal_thermal = "/thermal-zones/versal-thermal";
                temp_alert_aie = "/thermal-zones/versal-aie-thermal/trips/temp-alert-aie";
                ot_crit_aie = "/thermal-zones/versal-aie-thermal/trips/ot-crit-aie";
                versal_thermal_aie = "/thermal-zones/versal-aie-thermal";
                can0 = "/axi/can@ff060000";
                can1 = "/axi/can@ff070000";
                cci_pmu = "/axi/cci@fd000000/pmu@10000";
                cci = "/axi/cci@fd000000";
                lpd_dma_chan0 = "/axi/dma-controller@ffa80000";
                lpd_dma_chan1 = "/axi/dma-controller@ffa90000";
                lpd_dma_chan2 = "/axi/dma-controller@ffaa0000";
                lpd_dma_chan3 = "/axi/dma-controller@ffab0000";
                lpd_dma_chan4 = "/axi/dma-controller@ffac0000";
                lpd_dma_chan5 = "/axi/dma-controller@ffad0000";
                lpd_dma_chan6 = "/axi/dma-controller@ffae0000";
                lpd_dma_chan7 = "/axi/dma-controller@ffaf0000";
                phy1 = "/axi/ethernet@ff0c0000/mdio/ethernet-phy@1";
                mdio = "/axi/ethernet@ff0c0000/mdio";
                gem0 = "/axi/ethernet@ff0c0000";
                gem1 = "/axi/ethernet@ff0d0000";
                gpio0 = "/axi/gpio@ff0b0000";
                gpio1 = "/axi/gpio@f1020000";
                i2c0 = "/axi/i2c@ff020000";
                eeprom = "/axi/i2c@ff030000/eeprom@54";
                i2c1 = "/axi/i2c@ff030000";
                i2c2 = "/axi/i2c@f1000000";
                mc0 = "/axi/memory-controller@f6150000";
                mc1 = "/axi/memory-controller@f62c0000";
                mc2 = "/axi/memory-controller@f6430000";
                mc3 = "/axi/memory-controller@f65a0000";
                ocm = "/axi/memory-controller@ff960000";
                rtc = "/axi/rtc@f12a0000";
                sdhci0 = "/axi/mmc@f1040000";
                sdhci1 = "/axi/mmc@f1050000";
                serial0 = "/axi/serial@ff000000";
                serial1 = "/axi/serial@ff010000";
                smmu = "/axi/iommu@fd800000";
                ospi = "/axi/spi@f1010000";
                qspi = "/axi/spi@f1030000";
                spi0 = "/axi/spi@ff040000";
                spi1 = "/axi/spi@ff050000";
                sysmon0 = "/axi/sysmon@f1270000";
                sysmon1 = "/axi/sysmon@109270000";
                sysmon2 = "/axi/sysmon@111270000";
                sysmon3 = "/axi/sysmon@119270000";
                ttc1 = "/axi/timer@ff0f0000";
                ttc2 = "/axi/timer@ff100000";
                ttc3 = "/axi/timer@ff110000";
                dwc3_0 = "/axi/usb@ff9d0000/usb@fe200000";
                usb0 = "/axi/usb@ff9d0000";
                pcie_intc_0 = "/axi/pci@fca10000/interrupt-controller";
                cpm_pciea = "/axi/pci@fca10000";
                pcie_intc_2 = "/axi/pcie@fcdd0000/interrupt-controller";
                cpm5_pcie = "/axi/pcie@fcdd0000";
                watchdog = "/axi/watchdog@fd4d0000";
                watchdog1 = "/axi/watchdog@ff120000";
                xilsem_edac = "/axi/edac@f2014050";
                dma0 = "/axi/pmcdma@f11c0000";
                dma1 = "/axi/pmcdma@f11d0000";
                ipi_0_to_ipi_0 = "/axi/mailbox@ff330000/child@ff330000";
                ipi_0_to_ipi_1 = "/axi/mailbox@ff330000/child@ff340000";
                ipi_0_to_ipi_2 = "/axi/mailbox@ff330000/child@ff350000";
                ipi_0_to_ipi_3 = "/axi/mailbox@ff330000/child@ff360000";
                ipi_0_to_ipi_4 = "/axi/mailbox@ff330000/child@ff370000";
                ipi_0_to_ipi_5 = "/axi/mailbox@ff330000/child@ff380000";
                ipi_0_to_ipi_6 = "/axi/mailbox@ff330000/child@ff3a0000";
                ipi_0_to_ipi_pmc = "/axi/mailbox@ff330000/child@ff320000";
                ipi_0_to_ipi_pmc_nobuf = "/axi/mailbox@ff330000/child@ff390000";
                ipi_0_to_ipi_psm = "/axi/mailbox@ff330000/child@ff310000";
                ipi0 = "/axi/mailbox@ff330000";
                ipi_3_to_ipi_0 = "/axi/mailbox@ff360000/child@ff330000";
                ipi_3_to_ipi_1 = "/axi/mailbox@ff360000/child@ff340000";
                ipi_3_to_ipi_2 = "/axi/mailbox@ff360000/child@ff350000";
                ipi_3_to_ipi_3 = "/axi/mailbox@ff360000/child@ff360000";
                ipi_3_to_ipi_4 = "/axi/mailbox@ff360000/child@ff370000";
                ipi_3_to_ipi_5 = "/axi/mailbox@ff360000/child@ff380000";
                ipi_3_to_ipi_6 = "/axi/mailbox@ff360000/child@ff3a0000";
                ipi_3_to_ipi_pmc = "/axi/mailbox@ff360000/child@ff320000";
                ipi_3_to_ipi_pmc_nobuf = "/axi/mailbox@ff360000/child@ff390000";
                ipi_3_to_ipi_psm = "/axi/mailbox@ff360000/child@ff310000";
                ipi3 = "/axi/mailbox@ff360000";
                ipi_4_to_ipi_0 = "/axi/mailbox@ff370000/child@ff330000";
                ipi_4_to_ipi_1 = "/axi/mailbox@ff370000/child@ff340000";
                ipi_4_to_ipi_2 = "/axi/mailbox@ff370000/child@ff350000";
                ipi_4_to_ipi_3 = "/axi/mailbox@ff370000/child@ff360000";
                ipi_4_to_ipi_4 = "/axi/mailbox@ff370000/child@ff370000";
                ipi_4_to_ipi_5 = "/axi/mailbox@ff370000/child@ff380000";
                ipi_4_to_ipi_6 = "/axi/mailbox@ff370000/child@ff3a0000";
                ipi_4_to_ipi_pmc = "/axi/mailbox@ff370000/child@ff320000";
                ipi_4_to_ipi_pmc_nobuf = "/axi/mailbox@ff370000/child@ff390000";
                ipi_4_to_ipi_psm = "/axi/mailbox@ff370000/child@ff310000";
                ipi4 = "/axi/mailbox@ff370000";
                ipi_5_to_ipi_0 = "/axi/mailbox@ff380000/child@ff330000";
                ipi_5_to_ipi_1 = "/axi/mailbox@ff380000/child@ff340000";
                ipi_5_to_ipi_2 = "/axi/mailbox@ff380000/child@ff350000";
                ipi_5_to_ipi_3 = "/axi/mailbox@ff380000/child@ff360000";
                ipi_5_to_ipi_4 = "/axi/mailbox@ff380000/child@ff370000";
                ipi_5_to_ipi_5 = "/axi/mailbox@ff380000/child@ff380000";
                ipi_5_to_ipi_6 = "/axi/mailbox@ff380000/child@ff3a0000";
                ipi_5_to_ipi_pmc = "/axi/mailbox@ff380000/child@ff320000";
                ipi_5_to_ipi_pmc_nobuf = "/axi/mailbox@ff380000/child@ff390000";
                ipi_5_to_ipi_psm = "/axi/mailbox@ff380000/child@ff310000";
                ipi5 = "/axi/mailbox@ff380000";
                ipi_6_to_ipi_0 = "/axi/mailbox@ff3a0000/child@ff330000";
                ipi_6_to_ipi_1 = "/axi/mailbox@ff3a0000/child@ff340000";
                ipi_6_to_ipi_2 = "/axi/mailbox@ff3a0000/child@ff350000";
                ipi_6_to_ipi_3 = "/axi/mailbox@ff3a0000/child@ff360000";
                ipi_6_to_ipi_4 = "/axi/mailbox@ff3a0000/child@ff370000";
                ipi_6_to_ipi_5 = "/axi/mailbox@ff3a0000/child@ff380000";
                ipi_6_to_ipi_6 = "/axi/mailbox@ff3a0000/child@ff3a0000";
                ipi_6_to_ipi_pmc = "/axi/mailbox@ff3a0000/child@ff320000";
                ipi_6_to_ipi_pmc_nobuf = "/axi/mailbox@ff3a0000/child@ff390000";
                ipi_6_to_ipi_psm = "/axi/mailbox@ff3a0000/child@ff310000";
                ipi6 = "/axi/mailbox@ff3a0000";
                coresight = "/axi/coresight@f0800000";
                CIPS_0_pspmc_0_psv_coresight_fpd_cti1b = "/axi/CIPS_0_pspmc_0_psv_coresight_fpd_cti1b@f0bb0000";
                CIPS_0_pspmc_0_psv_coresight_fpd_cti1c = "/axi/CIPS_0_pspmc_0_psv_coresight_fpd_cti1c@f0bc0000";
                CIPS_0_pspmc_0_psv_coresight_fpd_cti1d = "/axi/CIPS_0_pspmc_0_psv_coresight_fpd_cti1d@f0bd0000";
                CIPS_0_pspmc_0_psv_coresight_lpd_cti = "/axi/CIPS_0_pspmc_0_psv_coresight_lpd_cti@f09d0000";
                CIPS_0_pspmc_0_psv_coresight_pmc_cti = "/axi/CIPS_0_pspmc_0_psv_coresight_pmc_cti@f08d0000";
                CIPS_0_pspmc_0_psv_coresight_r50_cti = "/axi/CIPS_0_pspmc_0_psv_coresight_r50_cti@f0a10000";
                CIPS_0_pspmc_0_psv_coresight_r51_cti = "/axi/CIPS_0_pspmc_0_psv_coresight_r51_cti@f0a50000";
                CIPS_0_pspmc_0_psv_cpm = "/axi/CIPS_0_pspmc_0_psv_cpm@0";
                CIPS_0_pspmc_0_psv_pmc_analog_0 = "/axi/CIPS_0_pspmc_0_psv_pmc_analog_0@f1160000";
                CIPS_0_pspmc_0_psv_pmc_iou_slcr_0 = "/axi/CIPS_0_pspmc_0_psv_pmc_iou_slcr_0@f1060000";
                CIPS_0_pspmc_0_psv_pmc_tap = "/axi/CIPS_0_pspmc_0_psv_pmc_tap@f11a0000";
                libmetal_uio_desc099c8000 = "/axi/libmetal_uio_desc0@99c8000";
                libmetal_uio_desc199cc000 = "/axi/libmetal_uio_desc1@99cc000";
                libmetal_uio_data99d0000 = "/axi/libmetal_uio_data@99d0000";
                gic_its = "/axi/interrupt-controller@f9000000/msi-controller@f9020000";
                gic = "/axi/interrupt-controller@f9000000";
                amba = "/axi";
                lpd_xppu = "/indirect-bus@1/xppu@ff990000";
                pmc_xppu = "/indirect-bus@1/xppu@f1310000";
                pmc_xppu_npi = "/indirect-bus@1/xppu@f1300000";
                amba_xppu = "/indirect-bus@1";
                fpd_xmpu = "/indirect-bus@2/xmpu@fd390000";
                pmc_xmpu = "/indirect-bus@2/xmpu@f12f0000";
                ocm_xmpu = "/indirect-bus@2/xmpu@ff980000";
                ddrmc_xmpu_0 = "/indirect-bus@2/xmpu@f6080000";
                ddrmc_xmpu_1 = "/indirect-bus@2/xmpu@f6220000";
                ddrmc_xmpu_2 = "/indirect-bus@2/xmpu@f6390000";
                ddrmc_xmpu_3 = "/indirect-bus@2/xmpu@f6500000";
                fpd_funnel_in_port1 = "/indirect-bus@2/fpd-funnel@f0b20000/in-ports/port@1/endpoint";
                fpd_funnel_out_port = "/indirect-bus@2/fpd-funnel@f0b20000/out-ports/port/endpoint";
                fpd_funnel = "/indirect-bus@2/fpd-funnel@f0b20000";
                fpd_etf_in_port = "/indirect-bus@2/fpd-etf@f0b30000/in-ports/port/endpoint";
                fpd_etf_out_port = "/indirect-bus@2/fpd-etf@f0b30000/out-ports/port/endpoint";
                fpd_etf = "/indirect-bus@2/fpd-etf@f0b30000";
                replicator_in_port = "/indirect-bus@2/replicator@f0b40000/in-ports/port/endpoint";
                replicator_out_port0 = "/indirect-bus@2/replicator@f0b40000/out-ports/port@0/endpoint";
                replicator = "/indirect-bus@2/replicator@f0b40000";
                etr_in_port = "/indirect-bus@2/etr@f0b50000/in-ports/port/endpoint";
                etr = "/indirect-bus@2/etr@f0b50000";
                funnel_in_port0 = "/indirect-bus@2/funnel@f0c20000/in-ports/port@0/endpoint";
                funnel_in_port1 = "/indirect-bus@2/funnel@f0c20000/in-ports/port@1/endpoint";
                funnel_out_port = "/indirect-bus@2/funnel@f0c20000/out-ports/port/endpoint";
                apu_funnel = "/indirect-bus@2/funnel@f0c20000";
                etf_in_port = "/indirect-bus@2/etf@f0c30000/in-ports/port/endpoint";
                apu_etf_out_port = "/indirect-bus@2/etf@f0c30000/out-ports/port/endpoint";
                apu_etf = "/indirect-bus@2/etf@f0c30000";
                cpu0_debug = "/indirect-bus@2/cpu0-debug@f0d00000";
                etm0_out_port = "/indirect-bus@2/etm@f0d30000/out-ports/port/endpoint";
                etm0 = "/indirect-bus@2/etm@f0d30000";
                cpu1_debug = "/indirect-bus@2/cpu1-debug@f0d40000";
                etm1_out_port = "/indirect-bus@2/etm@f0d70000/out-ports/port/endpoint";
                etm1 = "/indirect-bus@2/etm@f0d70000";
                amba_xmpu = "/indirect-bus@2";
                pl_alt_ref = "/pl-alt-ref";
                ref = "/ref";
                rtc_clk = "/rtc-clk";
                can0_clk = "/can0-clk";
                can1_clk = "/can1-clk";
                versal_clk = "/firmware/versal-firmware/clock-controller";
                zynqmp_power = "/firmware/versal-firmware/power-management";
                versal_reset = "/firmware/versal-firmware/reset-controller";
                pinctrl0 = "/firmware/versal-firmware/pinctrl";
                bbram_zeroize = "/firmware/versal-firmware/versal-sec-cfg/nvmem-layout/bbram-zeroize@4";
                bbram_key = "/firmware/versal-firmware/versal-sec-cfg/nvmem-layout/bbram-key@10";
                bbram_usr = "/firmware/versal-firmware/versal-sec-cfg/nvmem-layout/bbram-usr@30";
                bbram_lock = "/firmware/versal-firmware/versal-sec-cfg/nvmem-layout/bbram-lock@48";
                user_key0 = "/firmware/versal-firmware/versal-sec-cfg/nvmem-layout/user-key@110";
                user_key1 = "/firmware/versal-firmware/versal-sec-cfg/nvmem-layout/user-key@130";
                user_key2 = "/firmware/versal-firmware/versal-sec-cfg/nvmem-layout/user-key@150";
                user_key3 = "/firmware/versal-firmware/versal-sec-cfg/nvmem-layout/user-key@170";
                user_key4 = "/firmware/versal-firmware/versal-sec-cfg/nvmem-layout/user-key@190";
                user_key5 = "/firmware/versal-firmware/versal-sec-cfg/nvmem-layout/user-key@1b0";
                user_key6 = "/firmware/versal-firmware/versal-sec-cfg/nvmem-layout/user-key@1d0";
                user_key7 = "/firmware/versal-firmware/versal-sec-cfg/nvmem-layout/user-key@1f0";
                versal_sec_cfg = "/firmware/versal-firmware/versal-sec-cfg";
                versal_firmware = "/firmware/versal-firmware";
                noc_ddr0_ddr_memory = "/memory@00000000";
                noc_hbm_hbm_memory = "/memory@4000000000";
                noc_ddr1_ddr_memory = "/memory@50000000000";
                vdev0vring0 = "/reserved-memory/vdev0vring0@9880000";
                vdev0vring1 = "/reserved-memory/vdev0vring1@9884000";
                vdev0buffer = "/reserved-memory/vdev0buffer@9888000";
                trace_buffer = "/reserved-memory/trace@985f000";
                rproc0 = "/reserved-memory/rproc0@9800000";
                rsctbl = "/reserved-memory/rsctbl@9820000";
                libmetal_elf = "/reserved-memory/libmetal_elf@9968000";
                libmetal_desc0 = "/reserved-memory/libmetal_desc0@99c8000";
                libmetal_desc1 = "/reserved-memory/libmetal_desc1@99cc000";
                libmetal_data = "/reserved-memory/libmetal_data@99d0000";
                spi_flash = "/axi/spi@f1010000/flash@0";
        };

        reserved-memory {
                #address-cells = <0x2>;
                #size-cells = <0x2>;
                ranges;

                vdev0vring0: vdev0vring0@9880000 {
                        phandle = <0x18a>;
                        reg = <0x0 0x9880000 0x0 0x4000>;
                        no-map;
                        label = "vdev0vring0";
                };

                vdev0vring1: vdev0vring1@9884000 {
                        phandle = <0x189>;
                        reg = <0x0 0x9884000 0x0 0x4000>;
                        no-map;
                        label = "vdev0vring1";
                };

                vdev0buffer: vdev0buffer@9888000 {
                        phandle = <0x188>;
                        reg = <0x0 0x9888000 0x0 0x78000>;
                        no-map;
                        label = "vdev0buffer";
                        compatible = "shared-dma-pool";
                };

                trace_buffer: trace@985f000 {
                        phandle = <0x18c>;
                        reg = <0x0 0x985f000 0x0 0x1000>;
                        no-map;
                        mpu-policy = "readable", "writable";
                        label = "trace_buffer";
                };

                rproc0: rproc0@9800000 {
                        phandle = <0x18b>;
                        reg = <0x0 0x9800000 0x0 0x20000>;
                        no-map;
                        mpu-policy = "readable", "writable", "executable", "cacheable", "static";
                        label = "rproc0";
                };

                rsctbl: rsctbl@9820000 {
                        phandle = <0x18d>;
                        reg = <0x0 0x9820000 0x0 0x100>;
                        no-map;
                        mpu-policy = "readable", "writable";
                        label = "rsctbl";
                };

                libmetal_elf: libmetal_elf@9968000 {
                        phandle = <0x194>;
                        reg = <0x0 0x9968000 0x0 0x60000>;
                        no-map;
                        label = "libmetal_elf";
                };

                libmetal_desc0: libmetal_desc0@99c8000 {
                        phandle = <0x191>;
                        reg = <0x0 0x99c8000 0x0 0x4000>;
                        no-map;
                        label = "libmetal_desc0";
                };

                libmetal_desc1: libmetal_desc1@99cc000 {
                        phandle = <0x192>;
                        reg = <0x0 0x99cc000 0x0 0x4000>;
                        no-map;
                        label = "libmetal_desc1";
                };

                libmetal_data: libmetal_data@99d0000 {
                        phandle = <0x193>;
                        reg = <0x0 0x99d0000 0x0 0x40000>;
                        no-map;
                        label = "libmetal_data";
                };
        };

        remoteproc@ffe00000 {
                compatible = "xlnx,versal-r5fss";
                #address-cells = <0x2>;
                #size-cells = <0x2>;
                xlnx,cluster-mode = <0x0>;
                ranges = <0x0 0x0 0x0 0xffe00000 0x0 0x10000 0x0 0x20000 0x0 0xffe20000 0x0 0x10000>;
                xlnx,tcm-mode = <0x0>;

                r5f@0 {
                        compatible = "xlnx,versal-r5f";
                        power-domains = <&versal_firmware 0x18110005>,
                         <&versal_firmware 0x1831800b>,
                         <&versal_firmware 0x1831800c>;
                        reg = <0x0 0x0 0x0 0x10000 0x0 0x20000 0x0 0x10000>;
                        reg-names = "atcm0", "btcm0";
                        memory-region = <&rproc0>,
                         <&trace_buffer>,
                         <&rsctbl>,
                         <&vdev0buffer>,
                         <&vdev0vring0>,
                         <&vdev0vring1>;
                        mboxes = <&ipi_3_to_ipi_1 0x0>,
                         <&ipi_3_to_ipi_1 0x1>;
                        mbox-names = "tx", "rx";
                };
        };
};
